VERSION "..\..\trunk\components\winTestMT\code\canApi\dbcFiles\canBus_07.dbc, created by Octave and generateRandomDbc.m on 21-Feb-2017"

NS_ :

BS_:

BU_: ECU

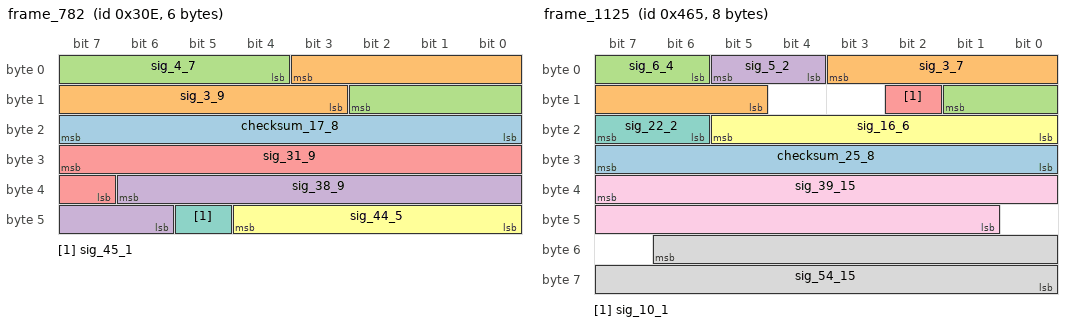
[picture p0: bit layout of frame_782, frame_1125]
BO_ 782 frame_782: 6 ECU
  SG_ checksum_17_8 : 23|8@0+ (1.0,0.0) [0.0|255.0] "" Vector__XXX
  SG_ sig_3_9 : 3|9@0- (1.0000000000000008E-8,3.162277660168379E-6) [6.02277660168377E-7|5.702277660168382E-6] "m/s^2" Vector__XXX
  SG_ sig_4_7 : 4|7@1+ (100.0,3162.2776601683795) [3162.2776601683795|15762.27766016838] "A" Vector__XXX
  SG_ sig_38_9 : 38|9@0+ (10.0,3162.2776601683795) [3162.2776601683795|8262.27766016838] "kWh" Vector__XXX
  SG_ sig_31_9 : 31|9@0+ (100.0,31622.776601683792) [31622.776601683792|82622.77660168378] "s" Vector__XXX
  SG_ sig_44_5 : 44|5@0- (0.1,0.0) [-1.6|1.4000000000000001] "m/s^2" Vector__XXX
  SG_ sig_45_1 : 45|1@0+ (1.0,0.0) [0.0|1.0] "" Vector__XXX

BO_ 1125 frame_1125: 8 Vector__XXX
  SG_ checksum_25_8 : 31|8@0+ (1.0,0.0) [0.0|255.0] "" ECU
  SG_ sig_3_7 : 3|7@0+ (1.0,0.0) [0.0|126.0] "" ECU
  SG_ sig_6_4 : 6|4@1- (1.0,0.0) [-8.0|6.0] "" ECU
  SG_ sig_5_2 : 5|2@0+ (1.0,0.0) [0.0|3.0] "" ECU
  SG_ sig_10_1 : 10|1@0+ (1.0,0.0) [0.0|1.0] "" ECU
  SG_ sig_16_6 : 16|6@1+ (1.0,0.0) [0.0|62.0] "" ECU
  SG_ sig_22_2 : 22|2@1+ (1.0,0.0) [0.0|3.0] "" ECU
  SG_ sig_54_15 : 54|15@0+ (1.0,31622.776601683792) [31622.776601683792|64388.77660168379] "A" ECU
  SG_ sig_39_15 : 39|15@0+ (1.0000000000000005E-4,3.1622776601683795) [3.1622776601683795|6.438877660168381] "m/s^2" ECU

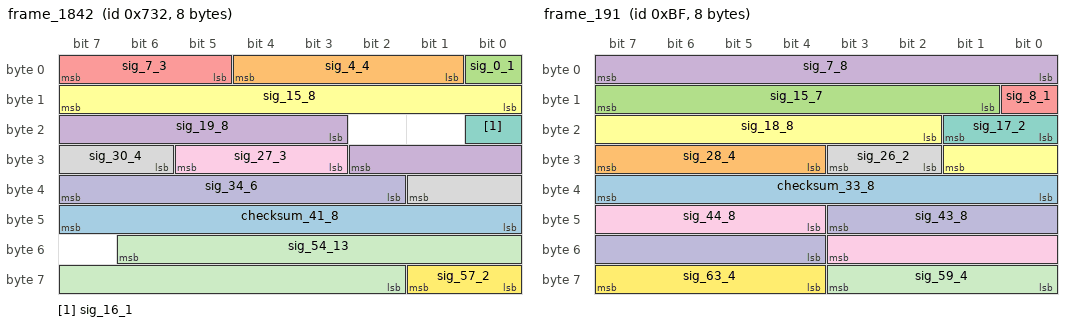
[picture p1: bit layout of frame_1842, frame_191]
BO_ 1842 frame_1842: 8 Vector__XXX
  SG_ checksum_41_8 : 47|8@0+ (1.0,0.0) [0.0|255.0] "" ECU
  SG_ sig_4_4 : 4|4@0+ (10000.0,0.0) [0.0|140000.0] "A" ECU
  SG_ sig_0_1 : 0|1@1+ (1.0,0.0) [0.0|1.0] "" ECU
  SG_ sig_19_8 : 19|8@1+ (1.0,0.0) [0.0|254.0] "A" ECU
  SG_ sig_7_3 : 7|3@0- (1.0,0.0) [-4.0|2.0] "" ECU
  SG_ sig_15_8 : 15|8@0+ (10.0,316.22776601683796) [316.22776601683796|2856.227766016838] "s" ECU
  SG_ sig_16_1 : 16|1@1+ (1.0,0.0) [0.0|1.0] "" ECU
  SG_ sig_30_4 : 30|4@1+ (10000.0,0.0) [0.0|140000.0] "A" ECU
  SG_ sig_27_3 : 27|3@1+ (1.0,0.0) [0.0|6.0] "" ECU
  SG_ sig_34_6 : 34|6@1+ (1.0000000000000006E-6,0.0) [0.0|6.200000000000004E-5] "kWh" ECU
  SG_ sig_54_13 : 54|13@0+ (10.0,-31622.776601683792) [-31622.776601683792|50277.22339831621] "A" ECU
  SG_ sig_57_2 : 57|2@0+ (1.0,0.0) [0.0|3.0] "" ECU

BO_ 1429 frame_1429: 4 Vector__XXX
  SG_ checksum_17_8 : 23|8@0+ (1.0,0.0) [0.0|255.0] "" ECU
  SG_ sig_3_10 : 3|10@0+ (0.010000000000000002,-3.1622776601683795) [-3.1622776601683795|7.0577223398316224] "A" ECU
  SG_ sig_7_4 : 7|4@0+ (0.010000000000000002,0.0) [0.0|0.14] "kWh" ECU
  SG_ sig_9_2 : 9|2@0- (1.0,0.0) [-2.0|1.0] "" ECU
  SG_ sig_31_8 : 31|8@0+ (1000.0,-31622.776601683792) [-31622.776601683792|222377.22339831622] "A" ECU

BO_ 191 frame_191: 8 Vector__XXX
  SG_ checksum_33_8 : 32|8@1+ (1.0,0.0) [0.0|255.0] "" ECU
  SG_ sig_28_4 : 28|4@1+ (10.0,0.0) [0.0|140.0] "km/h" ECU
  SG_ sig_15_7 : 15|7@0- (1.0,0.0) [-64.0|62.0] "" ECU
  SG_ sig_7_8 : 7|8@0- (1000.0,0.0) [-128000.0|126000.0] "A" ECU
  SG_ sig_8_1 : 8|1@1+ (1.0,0.0) [0.0|1.0] "" ECU
  SG_ sig_18_8 : 18|8@1+ (1.0000000000000005E-4,0.0) [0.0|0.025400000000000013] "W" ECU
  SG_ sig_17_2 : 17|2@0+ (1.0,0.0) [0.0|3.0] "" ECU
  SG_ sig_26_2 : 26|2@1- (1.0,0.0) [-2.0|1.0] "" ECU
  SG_ sig_44_8 : 44|8@1+ (1.0000000000000006E-6,0.0) [0.0|2.5400000000000016E-4] "s" ECU
  SG_ sig_43_8 : 43|8@0+ (0.010000000000000002,0.0) [0.0|2.5400000000000005] "s" ECU
  SG_ sig_59_4 : 59|4@0+ (1.0000000000000006E-6,0.0) [0.0|1.4000000000000008E-5] "kWh" ECU
  SG_ sig_63_4 : 63|4@0+ (1.0,0.0) [0.0|14.0] "m/s^2" ECU

BO_ 1867 frame_1867: 4 ECU
  SG_ checksum_1_8 : 0|8@1+ (1.0,0.0) [0.0|255.0] "" Vector__XXX
  SG_ sig_10_7 : 10|7@0+ (1.0000000000000006E-6,-3.1622776601683795E-5) [-3.1622776601683795E-5|9.437722339831629E-5] "V" Vector__XXX
  SG_ sig_15_5 : 15|5@0+ (0.1,0.0) [0.0|3.0] "m/s^2" Vector__XXX
  SG_ sig_17_10 : 17|10@0+ (10.0,0.0) [0.0|10220.0] "A" Vector__XXX
  SG_ sig_19_2 : 19|2@0+ (1.0,0.0) [0.0|3.0] "" Vector__XXX

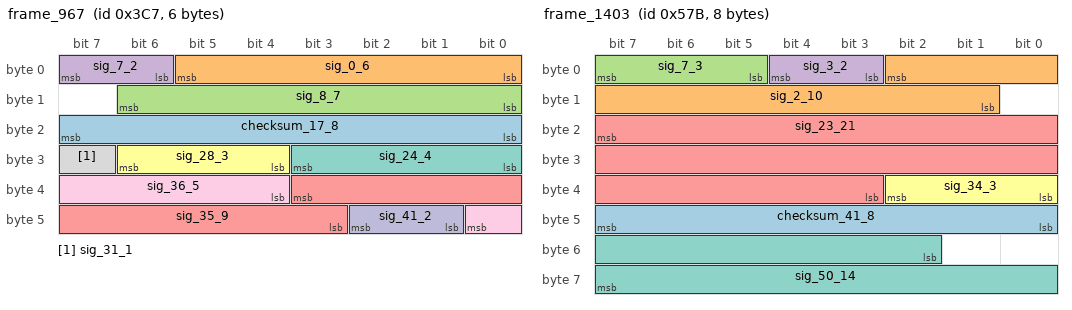
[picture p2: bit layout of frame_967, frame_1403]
BO_ 967 frame_967: 6 Vector__XXX
  SG_ checksum_17_8 : 16|8@1+ (1.0,0.0) [0.0|255.0] "" ECU
  SG_ sig_0_6 : 0|6@1+ (1.0000000000000007E-7,-3.162277660168379E-6) [-3.162277660168379E-6|3.037722339831626E-6] "A" ECU
  SG_ sig_8_7 : 8|7@1- (0.1,3.1622776601683795) [-3.237722339831621|9.36227766016838] "A" ECU
  SG_ sig_7_2 : 7|2@0+ (1.0,0.0) [0.0|3.0] "" ECU
  SG_ sig_35_9 : 35|9@0- (1.0000000000000006E-6,3.1622776601683794E-4) [6.022776601683779E-5|5.70227766016838E-4] "A" ECU
  SG_ sig_28_3 : 28|3@1- (1.0,0.0) [-4.0|2.0] "" ECU
  SG_ sig_24_4 : 24|4@1- (1.0,0.0) [-8.0|6.0] "" ECU
  SG_ sig_31_1 : 31|1@1+ (1.0,0.0) [0.0|1.0] "" ECU
  SG_ sig_36_5 : 36|5@1- (1.0,0.0) [-16.0|14.0] "" ECU
  SG_ sig_41_2 : 41|2@1+ (1.0,0.0) [0.0|3.0] "" ECU

BO_ 61 frame_61: 7 ECU
  SG_ checksum_17_8 : 23|8@0+ (1.0,0.0) [0.0|255.0] "" Vector__XXX
  SG_ sig_46_13 : 46|13@0- (1.0,0.0) [-4096.0|4094.0] "" Vector__XXX
  SG_ sig_47_3 : 47|3@1+ (1.0,0.0) [0.0|6.0] "" Vector__XXX

BO_ 1403 frame_1403: 8 ECU
  SG_ checksum_41_8 : 40|8@1+ (1.0,0.0) [0.0|255.0] "" Vector__XXX
  SG_ sig_2_10 : 2|10@0+ (1.0,0.0) [0.0|1022.0] "" Vector__XXX
  SG_ sig_7_3 : 7|3@0- (1.0,0.0) [-4.0|2.0] "" Vector__XXX
  SG_ sig_3_2 : 3|2@1+ (1.0,0.0) [0.0|3.0] "" Vector__XXX
  SG_ sig_23_21 : 23|21@0- (0.010000000000000002,-3162.2776601683795) [-13648.037660168382|7323.462339831622] "s" Vector__XXX
  SG_ sig_34_3 : 34|3@0- (1.0,0.0) [-4.0|2.0] "" Vector__XXX
  SG_ sig_50_14 : 50|14@1- (1.0000000000000009E-9,-3.162277660168379E-6) [-1.1354277660168386E-5|5.027722339831629E-6] "m/s^2" Vector__XXX

BO_ 1948 frame_1948: 6 Vector__XXX
  SG_ checksum_9_8 : 8|8@1+ (1.0,0.0) [0.0|255.0] "" ECU
  SG_ sig_0_8 : 0|8@1- (1.0000000000000007E-7,0.0) [-1.280000000000001E-5|1.260000000000001E-5] "m/s^2" ECU
  SG_ sig_21_10 : 21|10@1- (1.0,0.0) [-512.0|510.0] "" ECU
  SG_ sig_16_5 : 16|5@1- (1.0,0.0) [-16.0|14.0] "" ECU

BO_ 462 frame_462: 3 Vector__XXX
  SG_ checksum_17_8 : 23|8@0+ (1.0,0.0) [0.0|255.0] "" ECU
  SG_ sig_7_12 : 7|12@0- (0.0010000000000000002,-3.1622776601683795) [-5.21027766016838|-1.1162776601683788] "km/h" ECU
  SG_ sig_10_3 : 10|3@0+ (1.0,0.0) [0.0|6.0] "" ECU
  SG_ sig_11_1 : 11|1@0+ (1.0,0.0) [0.0|1.0] "" ECU

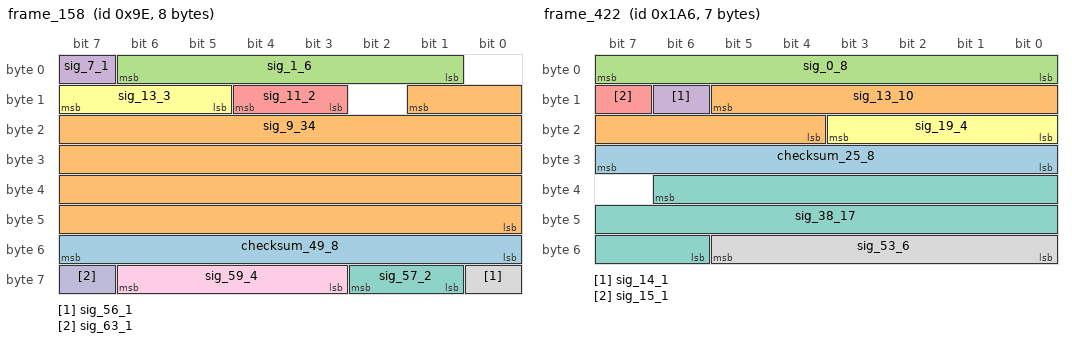
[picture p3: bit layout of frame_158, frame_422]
BO_ 158 frame_158: 8 ECU
  SG_ checksum_49_8 : 55|8@0+ (1.0,0.0) [0.0|255.0] "" Vector__XXX
  SG_ sig_9_34 : 9|34@0+ (1.0000000000000009E-9,3.1622776601683795) [3.1622776601683795|20.342146842168393] "m/s^2" Vector__XXX
  SG_ sig_1_6 : 1|6@1+ (0.0010000000000000002,0.03162277660168379) [0.03162277660168379|0.0936227766016838] "V" Vector__XXX
  SG_ sig_7_1 : 7|1@0+ (1.0,0.0) [0.0|1.0] "" Vector__XXX
  SG_ sig_11_2 : 11|2@1+ (1.0,0.0) [0.0|3.0] "" Vector__XXX
  SG_ sig_13_3 : 13|3@1- (1.0,0.0) [-4.0|2.0] "" Vector__XXX
  SG_ sig_57_2 : 57|2@1+ (1.0,0.0) [0.0|3.0] "" Vector__XXX
  SG_ sig_56_1 : 56|1@1+ (1.0,0.0) [0.0|1.0] "" Vector__XXX
  SG_ sig_59_4 : 59|4@1- (1.0,0.0) [-8.0|6.0] "" Vector__XXX
  SG_ sig_63_1 : 63|1@0+ (1.0,0.0) [0.0|1.0] "" Vector__XXX

BO_ 673 frame_673: 6 Vector__XXX
  SG_ checksum_25_8 : 31|8@0+ (1.0,0.0) [0.0|255.0] "" ECU
  SG_ sig_13_8 : 13|8@1- (1.0000000000000007E-7,-3.162277660168379E-6) [-1.596227766016839E-5|9.43772233983163E-6] "A" ECU
  SG_ sig_1_2 : 1|2@0- (1.0,0.0) [-2.0|1.0] "" ECU
  SG_ sig_12_1 : 12|1@0+ (1.0,0.0) [0.0|1.0] "" ECU
  SG_ sig_21_3 : 21|3@1+ (1.0,0.0) [0.0|6.0] "" ECU
  SG_ sig_37_12 : 37|12@0- (1.0000000000000006E-5,0.0) [-0.020480000000000012|0.020460000000000013] "m/s^2" ECU
  SG_ sig_41_1 : 41|1@0+ (1.0,0.0) [0.0|1.0] "" ECU

BO_ 422 frame_422: 7 Vector__XXX
  SG_ checksum_25_8 : 31|8@0+ (1.0,0.0) [0.0|255.0] "" ECU
  SG_ sig_13_10 : 13|10@0+ (1.0,0.0) [0.0|1022.0] "" ECU
  SG_ sig_0_8 : 0|8@1- (1.0000000000000005E-4,-0.0031622776601683794) [-0.015962277660168386|0.009437722339831625] "W" ECU
  SG_ sig_14_1 : 14|1@0+ (1.0,0.0) [0.0|1.0] "" ECU
  SG_ sig_15_1 : 15|1@0+ (1.0,0.0) [0.0|1.0] "" ECU
  SG_ sig_19_4 : 19|4@0+ (10.0,0.0) [0.0|140.0] "m/s^2" ECU
  SG_ sig_38_17 : 38|17@0- (1.0,0.0) [-65536.0|65534.0] "" ECU
  SG_ sig_53_6 : 53|6@0+ (1.0,0.0) [0.0|62.0] "" ECU

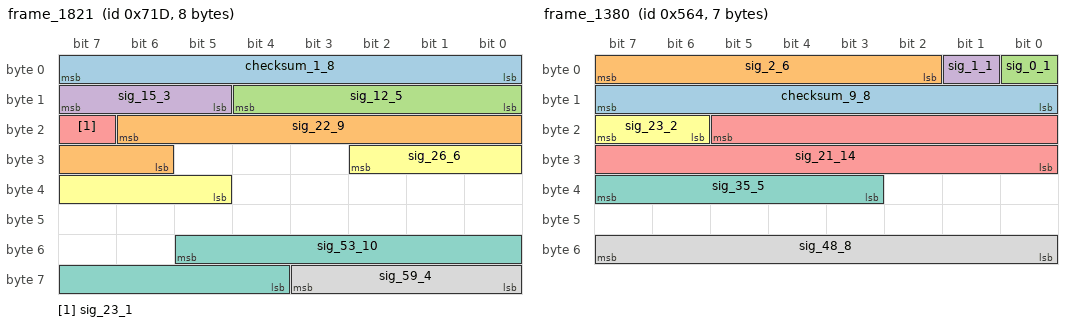
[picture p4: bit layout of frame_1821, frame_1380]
BO_ 1821 frame_1821: 8 Vector__XXX
  SG_ checksum_1_8 : 7|8@0+ (1.0,0.0) [0.0|255.0] "" ECU
  SG_ sig_22_9 : 22|9@0- (1.0,-316.22776601683796) [-572.2277660168379|-62.22776601683796] "kWh" ECU
  SG_ sig_12_5 : 12|5@0- (1.0,0.0) [-16.0|14.0] "" ECU
  SG_ sig_15_3 : 15|3@0- (1.0,0.0) [-4.0|2.0] "" ECU
  SG_ sig_23_1 : 23|1@0+ (1.0,0.0) [0.0|1.0] "" ECU
  SG_ sig_26_6 : 26|6@0+ (1.0000000000000005E-4,0.0031622776601683794) [0.0031622776601683794|0.009362277660168382] "W" ECU
  SG_ sig_53_10 : 53|10@0- (1.0000000000000008E-8,3.162277660168379E-6) [-1.957722339831625E-6|8.262277660168383E-6] "W" ECU
  SG_ sig_59_4 : 59|4@0- (10.0,0.0) [-80.0|60.0] "km/h" ECU

BO_ 1052 frame_1052: 3 ECU
  SG_ checksum_9_8 : 15|8@0+ (1.0,0.0) [0.0|255.0] "" Vector__XXX
  SG_ sig_7_8 : 7|8@0+ (0.1,0.0) [0.0|25.400000000000002] "W" Vector__XXX
  SG_ sig_22_7 : 22|7@0- (1.0,0.0) [-64.0|62.0] "" Vector__XXX
  SG_ sig_23_1 : 23|1@0+ (1.0,0.0) [0.0|1.0] "" Vector__XXX

BO_ 1380 frame_1380: 7 Vector__XXX
  SG_ checksum_9_8 : 8|8@1+ (1.0,0.0) [0.0|255.0] "" ECU
  SG_ sig_2_6 : 2|6@1- (1.0000000000000006E-5,-3.1622776601683794E-4) [-6.362277660168381E-4|-1.622776601683775E-5] "W" ECU
  SG_ sig_0_1 : 0|1@0+ (1.0,0.0) [0.0|1.0] "" ECU
  SG_ sig_1_1 : 1|1@1+ (1.0,0.0) [0.0|1.0] "" ECU
  SG_ sig_21_14 : 21|14@0+ (1.0000000000000007E-7,0.0) [0.0|0.0016382000000000013] "s" ECU
  SG_ sig_23_2 : 23|2@0+ (1.0,0.0) [0.0|3.0] "" ECU
  SG_ sig_35_5 : 35|5@1- (100.0,0.0) [-1600.0|1400.0] "V" ECU
  SG_ sig_48_8 : 48|8@1- (1.0,0.0) [-128.0|126.0] "" ECU

BO_ 1788 frame_1788: 3 Vector__XXX
  SG_ checksum_1_8 : 7|8@0+ (1.0,0.0) [0.0|255.0] "" ECU
  SG_ sig_13_14 : 13|14@0+ (1.0,0.0) [0.0|16382.0] "" ECU
  SG_ sig_15_2 : 15|2@0+ (1.0,0.0) [0.0|3.0] "" ECU

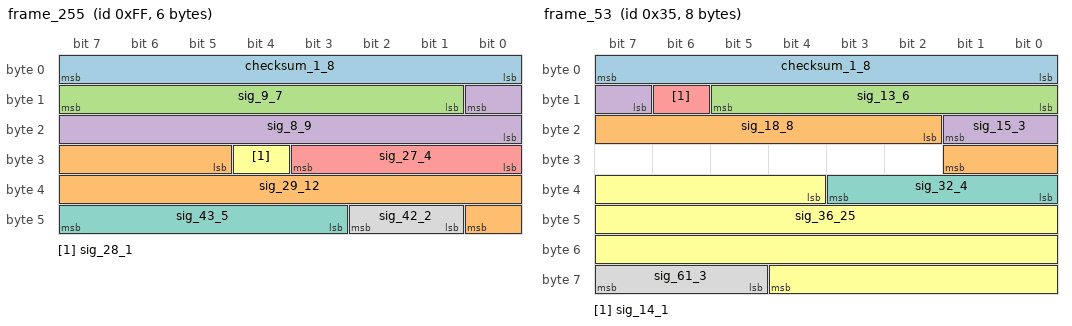
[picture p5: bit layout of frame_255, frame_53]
BO_ 255 frame_255: 6 Vector__XXX
  SG_ checksum_1_8 : 7|8@0+ (1.0,0.0) [0.0|255.0] "" ECU
  SG_ sig_29_12 : 29|12@1- (1.0,0.0) [-2048.0|2046.0] "" ECU
  SG_ sig_9_7 : 9|7@1- (1.0,0.0) [-64.0|62.0] "" ECU
  SG_ sig_8_9 : 8|9@0+ (0.0010000000000000002,-0.31622776601683794) [-0.31622776601683794|0.19377223398316218] "A" ECU
  SG_ sig_27_4 : 27|4@0- (0.1,0.31622776601683794) [-0.4837722339831621|0.9162277660168381] "W" ECU
  SG_ sig_28_1 : 28|1@1+ (1.0,0.0) [0.0|1.0] "" ECU
  SG_ sig_43_5 : 43|5@1+ (1.0000000000000006E-5,-3.1622776601683794E-4) [-3.1622776601683794E-4|-1.622776601683775E-5] "W" ECU
  SG_ sig_42_2 : 42|2@0+ (1.0,0.0) [0.0|3.0] "" ECU

BO_ 586 frame_586: 5 Vector__XXX
  SG_ checksum_17_8 : 16|8@1+ (1.0,0.0) [0.0|255.0] "" ECU
  SG_ sig_1_15 : 1|15@1+ (1.0,0.0) [0.0|32766.0] "" ECU
  SG_ sig_0_1 : 0|1@1+ (1.0,0.0) [0.0|1.0] "" ECU
  SG_ sig_26_8 : 26|8@1- (1.0,0.0) [-128.0|126.0] "" ECU
  SG_ sig_24_2 : 24|2@1+ (1.0,0.0) [0.0|3.0] "" ECU
  SG_ sig_35_5 : 35|5@1+ (1.0000000000000006E-5,3.1622776601683794E-4) [3.1622776601683794E-4|6.162277660168381E-4] "m/s^2" ECU
  SG_ sig_34_1 : 34|1@1+ (1.0,0.0) [0.0|1.0] "" ECU

BO_ 914 frame_914: 8 Vector__XXX
  SG_ checksum_33_8 : 39|8@0+ (1.0,0.0) [0.0|255.0] "" ECU
  SG_ sig_7_15 : 7|15@0- (1.0,0.0) [-16384.0|16382.0] "" ECU
  SG_ sig_8_17 : 8|17@0+ (1.0000000000000006E-6,0.0) [0.0|0.13107000000000008] "V" ECU
  SG_ sig_50_11 : 50|11@0- (1.0,0.0) [-1024.0|1022.0] "" ECU
  SG_ sig_47_13 : 47|13@0- (1.0000000000000008E-8,-3.1622776601683795E-5) [-7.258277660168383E-5|9.317223398316236E-6] "kWh" ECU

BO_ 565 frame_565: 5 Vector__XXX
  SG_ checksum_33_8 : 39|8@0+ (1.0,0.0) [0.0|255.0] "" ECU
  SG_ sig_6_24 : 6|24@1+ (1.000000000000001E-11,-3.1622776601683795E-5) [-3.1622776601683795E-5|1.361493633983164E-4] "m/s^2" ECU
  SG_ sig_5_1 : 5|1@0+ (1.0,0.0) [0.0|1.0] "" ECU
  SG_ sig_0_1 : 0|1@1+ (1.0,0.0) [0.0|1.0] "" ECU

BO_ 53 frame_53: 8 Vector__XXX
  SG_ checksum_1_8 : 0|8@1+ (1.0,0.0) [0.0|255.0] "" ECU
  SG_ sig_18_8 : 18|8@1+ (1.0,0.0) [0.0|254.0] "" ECU
  SG_ sig_13_6 : 13|6@0- (1.0,0.0) [-32.0|30.0] "" ECU
  SG_ sig_15_3 : 15|3@1- (1.0,0.0) [-4.0|2.0] "" ECU
  SG_ sig_14_1 : 14|1@1+ (1.0,0.0) [0.0|1.0] "" ECU
  SG_ sig_36_25 : 36|25@1- (1.0000000000000011E-10,-0.0031622776601683794) [-0.004839999260168381|-0.0014845562601683777] "kWh" ECU
  SG_ sig_32_4 : 32|4@1+ (1.0000000000000006E-5,0.0) [0.0|1.400000000000001E-4] "m/s^2" ECU
  SG_ sig_61_3 : 61|3@1+ (1.0,0.0) [0.0|6.0] "" ECU

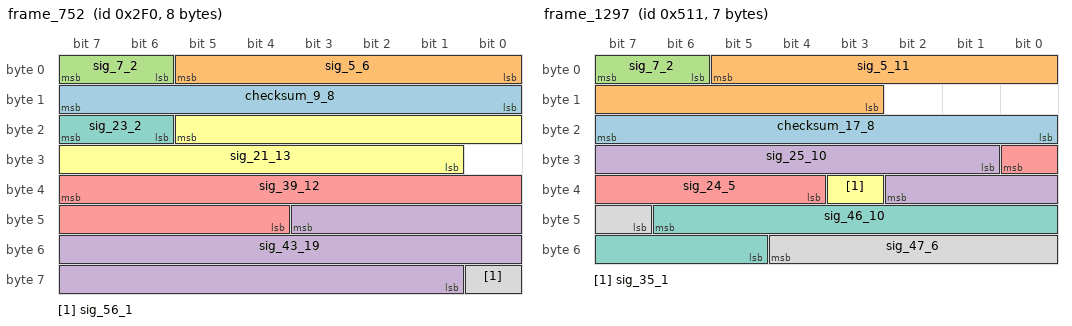
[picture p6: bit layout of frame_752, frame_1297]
BO_ 752 frame_752: 8 Vector__XXX
  SG_ checksum_9_8 : 15|8@0+ (1.0,0.0) [0.0|255.0] "" ECU
  SG_ sig_5_6 : 5|6@0- (1.0,31.622776601683793) [-0.37722339831620744|61.622776601683796] "V" ECU
  SG_ sig_7_2 : 7|2@0+ (1.0,0.0) [0.0|3.0] "" ECU
  SG_ sig_43_19 : 43|19@0+ (1.0000000000000005E-4,31.622776601683793) [31.622776601683793|84.05137660168381] "km/h" ECU
  SG_ sig_39_12 : 39|12@0- (1.0,0.0) [-2048.0|2046.0] "" ECU
  SG_ sig_21_13 : 21|13@0+ (1.0000000000000009E-9,-3.162277660168379E-6) [-3.162277660168379E-6|5.027722339831629E-6] "m/s^2" ECU
  SG_ sig_23_2 : 23|2@0- (1.0,0.0) [-2.0|1.0] "" ECU
  SG_ sig_56_1 : 56|1@0+ (1.0,0.0) [0.0|1.0] "" ECU

BO_ 1312 frame_1312: 4 Vector__XXX
  SG_ checksum_25_8 : 24|8@1+ (1.0,0.0) [0.0|255.0] "" ECU
  SG_ sig_15_10 : 15|10@0- (1.0,0.0) [-512.0|510.0] "" ECU
  SG_ sig_6_7 : 6|7@0- (1.0,-31.622776601683793) [-95.6227766016838|30.377223398316207] "V" ECU
  SG_ sig_7_1 : 7|1@0+ (1.0,0.0) [0.0|1.0] "" ECU
  SG_ sig_21_6 : 21|6@0+ (100.0,3162.2776601683795) [3162.2776601683795|9362.27766016838] "A" ECU

BO_ 863 frame_863: 7 Vector__XXX
  SG_ checksum_9_8 : 15|8@0+ (1.0,0.0) [0.0|255.0] "" ECU
  SG_ sig_0_8 : 0|8@1- (1.0000000000000006E-5,3.1622776601683794E-4) [-9.637722339831628E-4|0.0015762277660168386] "A" ECU
  SG_ sig_28_24 : 28|24@0+ (0.0010000000000000002,0.0) [0.0|16777.214000000004] "A" ECU
  SG_ sig_16_8 : 16|8@1- (1.0,0.0) [-128.0|126.0] "" ECU
  SG_ sig_31_3 : 31|3@0+ (1.0,0.0) [0.0|6.0] "" ECU
  SG_ sig_48_3 : 48|3@1+ (1.0,0.0) [0.0|6.0] "" ECU

BO_ 1297 frame_1297: 7 ECU
  SG_ checksum_17_8 : 16|8@1+ (1.0,0.0) [0.0|255.0] "" Vector__XXX
  SG_ sig_5_11 : 5|11@0+ (1.0,0.0) [0.0|2046.0] "m/s^2" Vector__XXX
  SG_ sig_7_2 : 7|2@0- (1.0,0.0) [-2.0|1.0] "" Vector__XXX
  SG_ sig_25_10 : 25|10@1- (1.0,0.0) [-512.0|510.0] "s" Vector__XXX
  SG_ sig_24_5 : 24|5@0+ (0.1,3.1622776601683795) [3.1622776601683795|6.16227766016838] "kWh" Vector__XXX
  SG_ sig_35_1 : 35|1@1+ (1.0,0.0) [0.0|1.0] "" Vector__XXX
  SG_ sig_46_10 : 46|10@0- (1.0000000000000007E-7,0.0) [-5.120000000000004E-5|5.100000000000004E-5] "W" Vector__XXX
  SG_ sig_47_6 : 47|6@1- (1.0000000000000006E-6,0.0) [-3.200000000000002E-5|3.0000000000000018E-5] "kWh" Vector__XXX

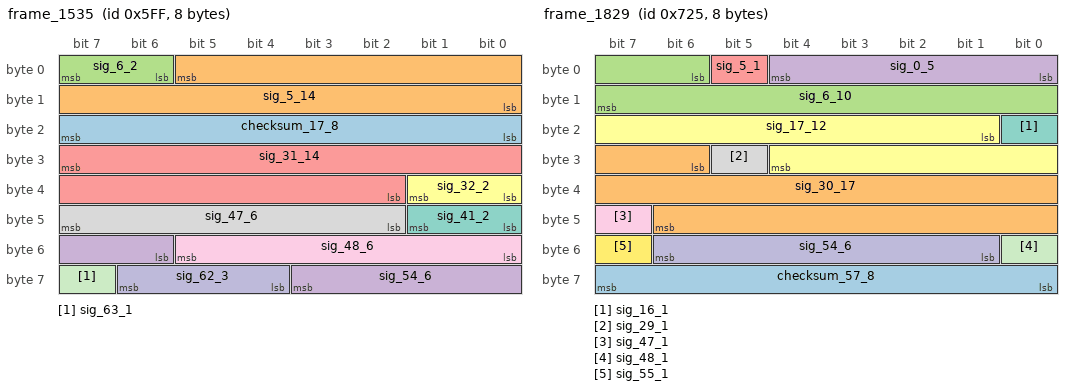
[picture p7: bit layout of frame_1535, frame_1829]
BO_ 1535 frame_1535: 8 Vector__XXX
  SG_ checksum_17_8 : 16|8@1+ (1.0,0.0) [0.0|255.0] "" ECU
  SG_ sig_5_14 : 5|14@0+ (0.1,316.22776601683796) [316.22776601683796|1954.427766016838] "m/s^2" ECU
  SG_ sig_6_2 : 6|2@1+ (1.0,0.0) [0.0|3.0] "" ECU
  SG_ sig_54_6 : 54|6@1- (1.0,0.0) [-32.0|30.0] "" ECU
  SG_ sig_31_14 : 31|14@0- (1.0000000000000005E-4,0.0) [-0.8192000000000004|0.8190000000000004] "s" ECU
  SG_ sig_32_2 : 32|2@1- (1.0,0.0) [-2.0|1.0] "" ECU
  SG_ sig_41_2 : 41|2@0- (1.0,0.0) [-2.0|1.0] "" ECU
  SG_ sig_47_6 : 47|6@0- (1.0,0.0) [-32.0|30.0] "" ECU
  SG_ sig_48_6 : 48|6@1- (1.0,0.0) [-32.0|30.0] "" ECU
  SG_ sig_62_3 : 62|3@0+ (1.0,0.0) [0.0|6.0] "" ECU
  SG_ sig_63_1 : 63|1@0+ (1.0,0.0) [0.0|1.0] "" ECU

BO_ 1829 frame_1829: 8 ECU
  SG_ checksum_57_8 : 63|8@0+ (1.0,0.0) [0.0|255.0] "" Vector__XXX
  SG_ sig_30_17 : 30|17@1+ (1.0,31622.776601683792) [31622.776601683792|162692.77660168378] "kWh" Vector__XXX
  SG_ sig_6_10 : 6|10@1- (0.1,0.0) [-51.2|51.0] "m/s^2" Vector__XXX
  SG_ sig_0_5 : 0|5@1+ (0.1,-3.1622776601683795) [-3.1622776601683795|-0.16227766016837952] "m/s^2" Vector__XXX
  SG_ sig_5_1 : 5|1@1+ (1.0,0.0) [0.0|1.0] "" Vector__XXX
  SG_ sig_17_12 : 17|12@1+ (1.0000000000000007E-7,3.1622776601683794E-4) [3.1622776601683794E-4|7.256277660168382E-4] "m/s^2" Vector__XXX
  SG_ sig_16_1 : 16|1@0+ (1.0,0.0) [0.0|1.0] "" Vector__XXX
  SG_ sig_29_1 : 29|1@1+ (1.0,0.0) [0.0|1.0] "" Vector__XXX
  SG_ sig_47_1 : 47|1@0+ (1.0,0.0) [0.0|1.0] "" Vector__XXX
  SG_ sig_54_6 : 54|6@0- (1.0,0.0) [-32.0|30.0] "" Vector__XXX
  SG_ sig_48_1 : 48|1@1+ (1.0,0.0) [0.0|1.0] "" Vector__XXX
  SG_ sig_55_1 : 55|1@1+ (1.0,0.0) [0.0|1.0] "" Vector__XXX

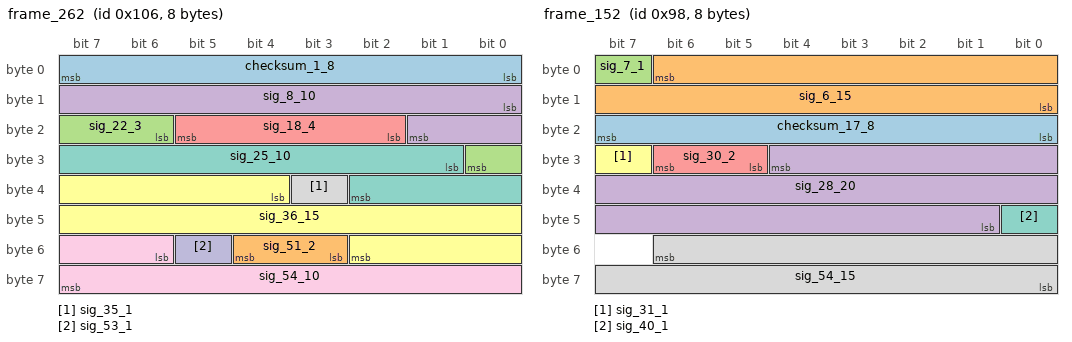
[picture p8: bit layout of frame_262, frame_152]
BO_ 262 frame_262: 8 Vector__XXX
  SG_ checksum_1_8 : 0|8@1+ (1.0,0.0) [0.0|255.0] "" ECU
  SG_ sig_51_2 : 51|2@1- (1.0,0.0) [-2.0|1.0] "" ECU
  SG_ sig_22_3 : 22|3@1+ (1.0,0.0) [0.0|6.0] "" ECU
  SG_ sig_8_10 : 8|10@1- (1.0000000000000008E-8,-3.162277660168379E-6) [-8.282277660168383E-6|1.9377223398316253E-6] "kWh" ECU
  SG_ sig_18_4 : 18|4@1- (10.0,31.622776601683793) [-48.377223398316204|91.6227766016838] "W" ECU
  SG_ sig_36_15 : 36|15@1+ (1.0000000000000006E-5,-0.31622776601683794) [-0.31622776601683794|0.011432233983162232] "m/s^2" ECU
  SG_ sig_25_10 : 25|10@1+ (0.1,-31.622776601683793) [-31.622776601683793|70.5772233983162] "A" ECU
  SG_ sig_35_1 : 35|1@1+ (1.0,0.0) [0.0|1.0] "" ECU
  SG_ sig_54_10 : 54|10@1+ (1.0,0.0) [0.0|1022.0] "" ECU
  SG_ sig_53_1 : 53|1@1+ (1.0,0.0) [0.0|1.0] "" ECU

BO_ 1208 frame_1208: 6 Vector__XXX
  SG_ checksum_25_8 : 24|8@1+ (1.0,0.0) [0.0|255.0] "" ECU
  SG_ sig_15_15 : 15|15@0+ (1.0,0.0) [0.0|32766.0] "" ECU
  SG_ sig_7_7 : 7|7@0+ (0.1,3.1622776601683795) [3.1622776601683795|15.762277660168381] "V" ECU
  SG_ sig_0_1 : 0|1@1+ (1.0,0.0) [0.0|1.0] "" ECU
  SG_ sig_16_1 : 16|1@1+ (1.0,0.0) [0.0|1.0] "" ECU
  SG_ sig_34_11 : 34|11@0- (1.0000000000000006E-5,-0.0031622776601683794) [-0.013402277660168386|0.007057722339831627] "km/h" ECU
  SG_ sig_35_5 : 35|5@1- (1.0,0.0) [-16.0|14.0] "" ECU

BO_ 1542 frame_1542: 5 Vector__XXX
  SG_ checksum_25_8 : 31|8@0+ (1.0,0.0) [0.0|255.0] "" ECU
  SG_ sig_12_12 : 12|12@0- (1.0000000000000006E-5,0.0) [-0.020480000000000012|0.020460000000000013] "m/s^2" ECU
  SG_ sig_0_7 : 0|7@1- (10.0,316.22776601683796) [-323.77223398316204|936.2277660168379] "km/h" ECU
  SG_ sig_7_1 : 7|1@1+ (1.0,0.0) [0.0|1.0] "" ECU
  SG_ sig_15_3 : 15|3@0- (1.0,0.0) [-4.0|2.0] "" ECU
  SG_ sig_16_1 : 16|1@1+ (1.0,0.0) [0.0|1.0] "" ECU
  SG_ sig_32_8 : 32|8@1- (10.0,-316.22776601683796) [-1596.227766016838|943.7722339831621] "A" ECU

BO_ 1341 frame_1341: 7 Vector__XXX
  SG_ checksum_41_8 : 40|8@1+ (1.0,0.0) [0.0|255.0] "" ECU
  SG_ sig_26_11 : 26|11@0- (1.0000000000000006E-6,3.1622776601683794E-4) [-7.077722339831627E-4|0.0013382277660168385] "A" ECU
  SG_ sig_19_9 : 19|9@0- (1.0000000000000006E-6,0.0) [-2.5600000000000015E-4|2.5400000000000016E-4] "km/h" ECU
  SG_ sig_48_8 : 48|8@1- (1.0,0.0) [-128.0|126.0] "" ECU

BO_ 1281 frame_1281: 6 ECU
  SG_ checksum_1_8 : 0|8@1+ (1.0,0.0) [0.0|255.0] "" Vector__XXX
  SG_ sig_13_17 : 13|17@1- (1.0000000000000007E-7,0.0) [-0.006553600000000005|0.006553400000000005] "V" Vector__XXX
  SG_ sig_11_4 : 11|4@0+ (1.0000000000000006E-6,3.162277660168379E-6) [3.162277660168379E-6|1.7162277660168386E-5] "kWh" Vector__XXX
  SG_ sig_12_1 : 12|1@1+ (1.0,0.0) [0.0|1.0] "" Vector__XXX
  SG_ sig_31_2 : 31|2@0+ (1.0,0.0) [0.0|3.0] "" Vector__XXX
  SG_ sig_39_15 : 39|15@0+ (1.0,-31622.776601683792) [-31622.776601683792|1143.2233983162077] "W" Vector__XXX
  SG_ sig_40_1 : 40|1@1+ (1.0,0.0) [0.0|1.0] "" Vector__XXX

BO_ 1119 frame_1119: 6 Vector__XXX
  SG_ checksum_1_8 : 0|8@1+ (1.0,0.0) [0.0|255.0] "" ECU
  SG_ sig_25_14 : 25|14@0- (1.0,0.0) [-8192.0|8190.0] "A" ECU
  SG_ sig_11_15 : 11|15@0+ (1.0000000000000011E-10,0.0) [0.0|3.2766000000000035E-6] "m/s^2" ECU
  SG_ sig_15_4 : 15|4@0- (1.0,0.0) [-8.0|6.0] "" ECU
  SG_ sig_28_3 : 28|3@0+ (1.0,0.0) [0.0|6.0] "" ECU
  SG_ sig_40_4 : 40|4@1+ (1.0,0.0) [0.0|14.0] "" ECU

BO_ 869 frame_869: 6 Vector__XXX
  SG_ checksum_1_8 : 0|8@1+ (1.0,0.0) [0.0|255.0] "" ECU
  SG_ sig_11_8 : 11|8@0+ (1.0,0.0) [0.0|254.0] "" ECU
  SG_ sig_15_3 : 15|3@0+ (1.0,0.0) [0.0|6.0] "" ECU
  SG_ sig_12_1 : 12|1@1+ (1.0,0.0) [0.0|1.0] "" ECU
  SG_ sig_16_4 : 16|4@1+ (1.0000000000000005E-4,3.1622776601683794E-4) [3.1622776601683794E-4|0.0017162277660168386] "s" ECU
  SG_ sig_30_18 : 30|18@0+ (1.0000000000000006E-6,-0.03162277660168379) [-0.03162277660168379|0.23051922339831638] "V" ECU

BO_ 1381 frame_1381: 8 Vector__XXX
  SG_ checksum_57_8 : 56|8@1+ (1.0,0.0) [0.0|255.0] "" ECU
  SG_ sig_0_54 : 0|54@1+ (1.0000000000000017E-16,0.31622776601683794) [0.31622776601683794|2.1176676169650395] "km/h" ECU
  SG_ sig_55_2 : 55|2@0+ (1.0,0.0) [0.0|3.0] "" ECU

BO_ 678 frame_678: 2 ECU
  SG_ checksum_1_8 : 7|8@0+ (1.0,0.0) [0.0|255.0] "" Vector__XXX
  SG_ sig_8_7 : 8|7@1+ (1000.0,0.0) [0.0|126000.0] "A" Vector__XXX
  SG_ sig_15_1 : 15|1@0+ (1.0,0.0) [0.0|1.0] "" Vector__XXX

BO_ 1157 frame_1157: 3 ECU
  SG_ checksum_9_8 : 15|8@0+ (1.0,0.0) [0.0|255.0] "" Vector__XXX
  SG_ sig_0_1 : 0|1@1+ (1.0,0.0) [0.0|1.0] "" Vector__XXX
  SG_ sig_16_7 : 16|7@1- (1.0000000000000006E-5,-3.1622776601683794E-4) [-9.562277660168383E-4|3.037722339831624E-4] "s" Vector__XXX
  SG_ sig_23_1 : 23|1@0+ (1.0,0.0) [0.0|1.0] "" Vector__XXX

BO_ 152 frame_152: 8 Vector__XXX
  SG_ checksum_17_8 : 16|8@1+ (1.0,0.0) [0.0|255.0] "" ECU
  SG_ sig_6_15 : 6|15@0+ (1.0000000000000005E-4,-3.1622776601683795) [-3.1622776601683795|0.11432233983162199] "W" ECU
  SG_ sig_7_1 : 7|1@1+ (1.0,0.0) [0.0|1.0] "" ECU
  SG_ sig_28_20 : 28|20@0+ (1.000000000000001E-11,-3.162277660168379E-6) [-3.162277660168379E-6|7.323462339831632E-6] "W" ECU
  SG_ sig_30_2 : 30|2@0- (1.0,0.0) [-2.0|1.0] "" ECU
  SG_ sig_31_1 : 31|1@0+ (1.0,0.0) [0.0|1.0] "" ECU
  SG_ sig_40_1 : 40|1@1+ (1.0,0.0) [0.0|1.0] "" ECU
  SG_ sig_54_15 : 54|15@0+ (1.0000000000000009E-9,0.0) [0.0|3.276600000000003E-5] "W" ECU

BO_ 1496 frame_1496: 6 Vector__XXX
  SG_ checksum_33_8 : 32|8@1+ (1.0,0.0) [0.0|255.0] "" ECU
  SG_ sig_1_10 : 1|10@1+ (1.0000000000000005E-4,0.0) [0.0|0.10220000000000004] "V" ECU
  SG_ sig_30_1 : 30|1@1+ (1.0,0.0) [0.0|1.0] "" ECU
  SG_ sig_31_1 : 31|1@0+ (1.0,0.0) [0.0|1.0] "" ECU
  SG_ sig_25_5 : 25|5@1- (1.0,0.0) [-16.0|14.0] "" ECU
  SG_ sig_40_8 : 40|8@1+ (0.010000000000000002,0.31622776601683794) [0.31622776601683794|2.8562277660168385] "s" ECU

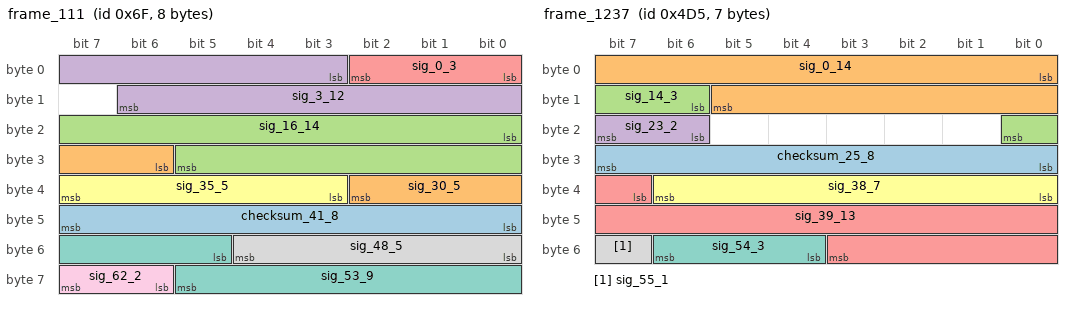
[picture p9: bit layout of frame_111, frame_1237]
BO_ 111 frame_111: 8 ECU
  SG_ checksum_41_8 : 40|8@1+ (1.0,0.0) [0.0|255.0] "" Vector__XXX
  SG_ sig_30_5 : 30|5@1+ (0.010000000000000002,0.31622776601683794) [0.31622776601683794|0.616227766016838] "km/h" Vector__XXX
  SG_ sig_16_14 : 16|14@1- (1.0,0.0) [-8192.0|8190.0] "" Vector__XXX
  SG_ sig_3_12 : 3|12@1- (1.0,0.0) [-2048.0|2046.0] "" Vector__XXX
  SG_ sig_0_3 : 0|3@1+ (1.0,0.0) [0.0|6.0] "" Vector__XXX
  SG_ sig_35_5 : 35|5@1+ (1.0000000000000006E-6,3.1622776601683795E-5) [3.1622776601683795E-5|6.162277660168381E-5] "kWh" Vector__XXX
  SG_ sig_53_9 : 53|9@1- (100.0,31622.776601683792) [6022.776601683792|57022.77660168379] "W" Vector__XXX
  SG_ sig_48_5 : 48|5@1+ (1.0,0.0) [0.0|30.0] "" Vector__XXX
  SG_ sig_62_2 : 62|2@1+ (1.0,0.0) [0.0|3.0] "" Vector__XXX

BO_ 1237 frame_1237: 7 Vector__XXX
  SG_ checksum_25_8 : 24|8@1+ (1.0,0.0) [0.0|255.0] "" ECU
  SG_ sig_0_14 : 0|14@1+ (1.0,0.0) [0.0|16382.0] "" ECU
  SG_ sig_14_3 : 14|3@1+ (1.0,0.0) [0.0|6.0] "" ECU
  SG_ sig_23_2 : 23|2@0+ (1.0,0.0) [0.0|3.0] "" ECU
  SG_ sig_39_13 : 39|13@1+ (1.0000000000000007E-7,-3.1622776601683794E-4) [-3.1622776601683794E-4|5.027722339831627E-4] "kWh" ECU
  SG_ sig_38_7 : 38|7@0- (10.0,316.22776601683796) [-323.77223398316204|936.2277660168379] "kWh" ECU
  SG_ sig_54_3 : 54|3@0+ (1.0,0.0) [0.0|6.0] "" ECU
  SG_ sig_55_1 : 55|1@1+ (1.0,0.0) [0.0|1.0] "" ECU

BO_ 509 frame_509: 6 ECU
  SG_ checksum_9_8 : 15|8@0+ (1.0,0.0) [0.0|255.0] "" Vector__XXX
  SG_ sig_7_7 : 7|7@0+ (1.0000000000000005E-4,-0.0031622776601683794) [-0.0031622776601683794|0.009437722339831625] "s" Vector__XXX
  SG_ sig_20_26 : 20|26@0- (1.0000000000000014E-12,-3.1622776601683795E-5) [-6.517720860168384E-5|1.9316533983162527E-6] "W" Vector__XXX
  SG_ sig_23_3 : 23|3@0+ (1.0,0.0) [0.0|6.0] "" Vector__XXX
  SG_ sig_42_3 : 42|3@0- (1.0,0.0) [-4.0|2.0] "" Vector__XXX

BO_ 927 frame_927: 4 Vector__XXX
  SG_ checksum_1_8 : 0|8@1+ (1.0,0.0) [0.0|255.0] "" ECU
  SG_ sig_9_14 : 9|14@1+ (1.0000000000000005E-4,0.31622776601683794) [0.31622776601683794|1.9544277660168388] "A" ECU
  SG_ sig_8_1 : 8|1@1+ (1.0,0.0) [0.0|1.0] "" ECU
  SG_ sig_23_8 : 23|8@1+ (1000.0,0.0) [0.0|254000.0] "V" ECU
  SG_ sig_31_1 : 31|1@1+ (1.0,0.0) [0.0|1.0] "" ECU

BO_ 199 frame_199: 4 ECU
  SG_ checksum_17_8 : 23|8@0+ (1.0,0.0) [0.0|255.0] "" Vector__XXX
  SG_ sig_3_11 : 3|11@1- (1.0000000000000006E-6,3.1622776601683794E-4) [-7.077722339831627E-4|0.0013382277660168385] "W" Vector__XXX
  SG_ sig_0_3 : 0|3@1+ (1.0,0.0) [0.0|6.0] "" Vector__XXX
  SG_ sig_14_2 : 14|2@1- (1.0,0.0) [-2.0|1.0] "" Vector__XXX
  SG_ sig_28_3 : 28|3@1- (1.0,0.0) [-4.0|2.0] "" Vector__XXX
  SG_ sig_31_1 : 31|1@0+ (1.0,0.0) [0.0|1.0] "" Vector__XXX
  SG_ sig_24_4 : 24|4@1+ (1.0,0.0) [0.0|14.0] "" Vector__XXX

BO_ 1601 frame_1601: 5 Vector__XXX
  SG_ checksum_1_8 : 7|8@0+ (1.0,0.0) [0.0|255.0] "" ECU
  SG_ sig_13_22 : 13|22@0- (1.0000000000000014E-12,-3.162277660168379E-6) [-5.259429660168382E-6|-1.0651276601683763E-6] "kWh" ECU
  SG_ sig_15_2 : 15|2@0- (1.0,0.0) [-2.0|1.0] "" ECU
  SG_ sig_33_6 : 33|6@1+ (1.0,0.0) [0.0|62.0] "" ECU
  SG_ sig_39_1 : 39|1@0+ (1.0,0.0) [0.0|1.0] "" ECU
  SG_ sig_32_1 : 32|1@0+ (1.0,0.0) [0.0|1.0] "" ECU

BO_ 1931 frame_1931: 5 ECU
  SG_ checksum_25_8 : 31|8@0+ (1.0,0.0) [0.0|255.0] "" Vector__XXX
  SG_ sig_1_14 : 1|14@0- (1.0000000000000007E-7,3.1622776601683794E-4) [-5.029722339831627E-4|0.0011352277660168384] "kWh" Vector__XXX
  SG_ sig_6_5 : 6|5@0+ (1.0,0.0) [0.0|30.0] "" Vector__XXX
  SG_ sig_7_1 : 7|1@0+ (1.0,0.0) [0.0|1.0] "" Vector__XXX
  SG_ sig_17_3 : 17|3@1- (1.0,0.0) [-4.0|2.0] "" Vector__XXX
  SG_ sig_39_8 : 39|8@0- (1.0000000000000005E-4,0.0) [-0.012800000000000006|0.012600000000000005] "V" Vector__XXX

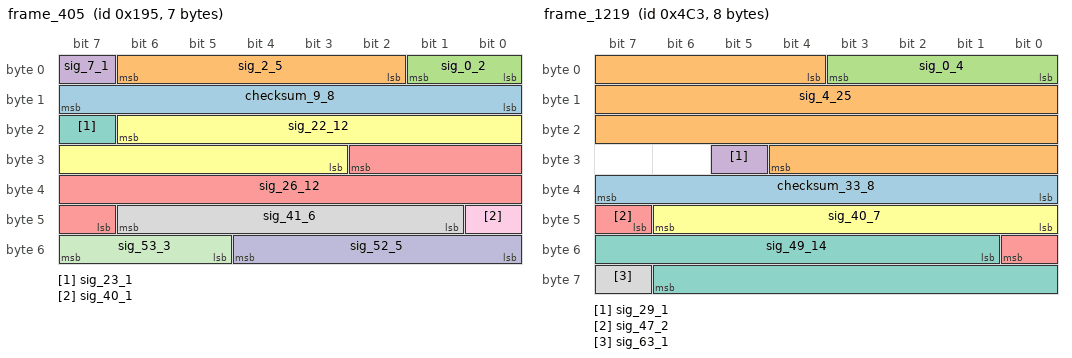
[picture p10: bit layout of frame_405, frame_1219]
BO_ 405 frame_405: 7 Vector__XXX
  SG_ checksum_9_8 : 8|8@1+ (1.0,0.0) [0.0|255.0] "" ECU
  SG_ sig_2_5 : 2|5@1+ (1.0,0.0) [0.0|30.0] "" ECU
  SG_ sig_0_2 : 0|2@1- (1.0,0.0) [-2.0|1.0] "" ECU
  SG_ sig_7_1 : 7|1@0+ (1.0,0.0) [0.0|1.0] "" ECU
  SG_ sig_26_12 : 26|12@0- (1.0000000000000008E-8,3.1622776601683795E-5) [1.1142776601683778E-5|5.208277660168381E-5] "km/h" ECU
  SG_ sig_22_12 : 22|12@0+ (1.0000000000000009E-9,3.162277660168379E-6) [3.162277660168379E-6|7.256277660168383E-6] "m/s^2" ECU
  SG_ sig_23_1 : 23|1@1+ (1.0,0.0) [0.0|1.0] "" ECU
  SG_ sig_41_6 : 41|6@1- (1.0000000000000006E-5,3.1622776601683794E-4) [-3.7722339831622494E-6|6.162277660168381E-4] "kWh" ECU
  SG_ sig_40_1 : 40|1@1+ (1.0,0.0) [0.0|1.0] "" ECU
  SG_ sig_52_5 : 52|5@0+ (0.010000000000000002,0.31622776601683794) [0.31622776601683794|0.616227766016838] "kWh" ECU
  SG_ sig_53_3 : 53|3@1- (1.0,0.0) [-4.0|2.0] "" ECU

BO_ 1219 frame_1219: 8 Vector__XXX
  SG_ checksum_33_8 : 39|8@0+ (1.0,0.0) [0.0|255.0] "" ECU
  SG_ sig_4_25 : 4|25@1- (0.0010000000000000002,31622.776601683792) [14845.560601683788|48399.99060168379] "A" ECU
  SG_ sig_0_4 : 0|4@1- (1.0,0.0) [-8.0|6.0] "" ECU
  SG_ sig_29_1 : 29|1@0+ (1.0,0.0) [0.0|1.0] "" ECU
  SG_ sig_47_2 : 47|2@1+ (1.0,0.0) [0.0|3.0] "" ECU
  SG_ sig_40_7 : 40|7@1- (1.0000000000000007E-7,0.0) [-6.400000000000005E-6|6.200000000000005E-6] "A" ECU
  SG_ sig_49_14 : 49|14@1+ (1.0,-3162.2776601683795) [-3162.2776601683795|13219.72233983162] "A" ECU
  SG_ sig_63_1 : 63|1@1+ (1.0,0.0) [0.0|1.0] "" ECU

BO_ 788 frame_788: 5 Vector__XXX
  SG_ checksum_17_8 : 23|8@0+ (1.0,0.0) [0.0|255.0] "" ECU
  SG_ sig_1_12 : 1|12@1- (1.0000000000000008E-8,3.1622776601683795E-5) [1.1142776601683778E-5|5.208277660168381E-5] "m/s^2" ECU
  SG_ sig_0_3 : 0|3@0- (1.0,0.0) [-4.0|2.0] "" ECU
  SG_ sig_13_1 : 13|1@1+ (1.0,0.0) [0.0|1.0] "" ECU
  SG_ sig_25_10 : 25|10@0+ (1.0,0.0) [0.0|1022.0] "" ECU
  SG_ sig_31_6 : 31|6@0+ (1.0000000000000006E-5,3.1622776601683794E-4) [3.1622776601683794E-4|9.362277660168383E-4] "s" ECU

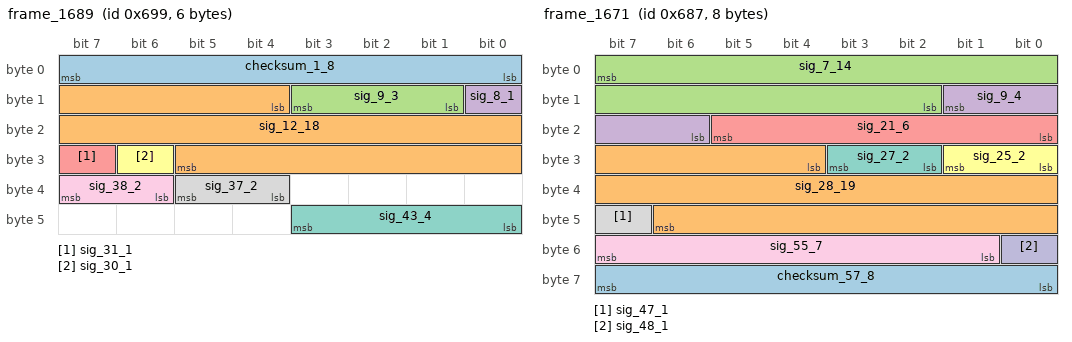
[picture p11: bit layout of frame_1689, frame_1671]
BO_ 1689 frame_1689: 6 Vector__XXX
  SG_ checksum_1_8 : 7|8@0+ (1.0,0.0) [0.0|255.0] "" ECU
  SG_ sig_12_18 : 12|18@1- (1.0,31622.776601683792) [-99449.22339831622|162692.77660168378] "W" ECU
  SG_ sig_9_3 : 9|3@1+ (1.0,0.0) [0.0|6.0] "" ECU
  SG_ sig_8_1 : 8|1@1+ (1.0,0.0) [0.0|1.0] "" ECU
  SG_ sig_31_1 : 31|1@0+ (1.0,0.0) [0.0|1.0] "" ECU
  SG_ sig_30_1 : 30|1@0+ (1.0,0.0) [0.0|1.0] "" ECU
  SG_ sig_43_4 : 43|4@0+ (0.1,0.31622776601683794) [0.31622776601683794|1.7162277660168381] "s" ECU
  SG_ sig_37_2 : 37|2@0- (1.0,0.0) [-2.0|1.0] "" ECU
  SG_ sig_38_2 : 38|2@1+ (1.0,0.0) [0.0|3.0] "" ECU

BO_ 42 frame_42: 8 Vector__XXX
  SG_ checksum_17_8 : 23|8@0+ (1.0,0.0) [0.0|255.0] "" ECU
  SG_ sig_7_15 : 7|15@0+ (1.0,0.0) [0.0|32766.0] "" ECU
  SG_ sig_8_1 : 8|1@1+ (1.0,0.0) [0.0|1.0] "" ECU
  SG_ sig_31_25 : 31|25@1- (1.0000000000000006E-5,316.22776601683796) [148.45560601683786|483.99990601683805] "kWh" ECU
  SG_ sig_24_5 : 24|5@1+ (1000.0,-31622.776601683792) [-31622.776601683792|-1622.7766016837923] "m/s^2" ECU
  SG_ sig_30_2 : 30|2@0+ (1.0,0.0) [0.0|3.0] "" ECU
  SG_ sig_57_6 : 57|6@1- (0.0010000000000000002,-0.03162277660168379) [-0.0636227766016838|-0.0016227766016837855] "km/h" ECU

BO_ 1671 frame_1671: 8 Vector__XXX
  SG_ checksum_57_8 : 63|8@0+ (1.0,0.0) [0.0|255.0] "" ECU
  SG_ sig_28_19 : 28|19@1+ (0.010000000000000002,3162.2776601683795) [3162.2776601683795|8405.13766016838] "kWh" ECU
  SG_ sig_7_14 : 7|14@0+ (0.010000000000000002,-31.622776601683793) [-31.622776601683793|132.19722339831623] "m/s^2" ECU
  SG_ sig_9_4 : 9|4@0- (1.0,0.0) [-8.0|6.0] "" ECU
  SG_ sig_21_6 : 21|6@0- (10.0,-316.22776601683796) [-636.2277660168379|-16.22776601683796] "A" ECU
  SG_ sig_25_2 : 25|2@0+ (1.0,0.0) [0.0|3.0] "" ECU
  SG_ sig_27_2 : 27|2@0+ (1.0,0.0) [0.0|3.0] "" ECU
  SG_ sig_47_1 : 47|1@0+ (1.0,0.0) [0.0|1.0] "" ECU
  SG_ sig_55_7 : 55|7@0+ (1.0000000000000005E-4,-0.0031622776601683794) [-0.0031622776601683794|0.009437722339831625] "s" ECU
  SG_ sig_48_1 : 48|1@0+ (1.0,0.0) [0.0|1.0] "" ECU

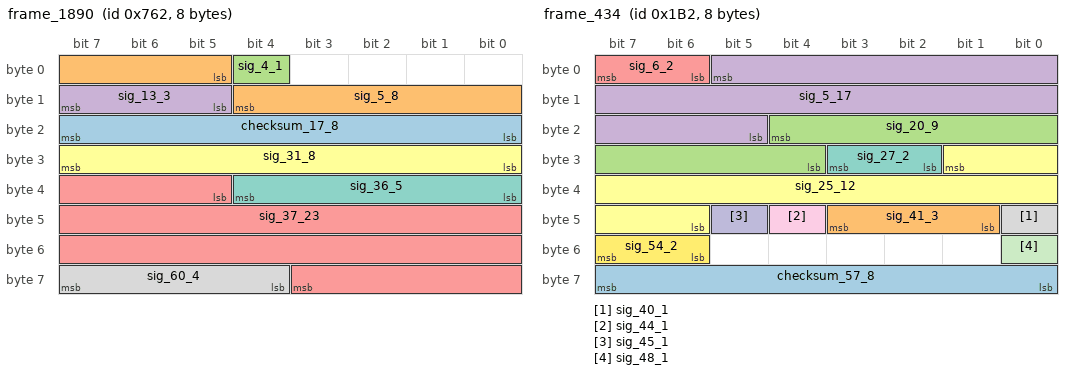
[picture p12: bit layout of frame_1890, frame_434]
BO_ 1890 frame_1890: 8 Vector__XXX
  SG_ checksum_17_8 : 16|8@1+ (1.0,0.0) [0.0|255.0] "" ECU
  SG_ sig_5_8 : 5|8@1- (0.0010000000000000002,0.03162277660168379) [-0.09637722339831624|0.15762277660168383] "kWh" ECU
  SG_ sig_4_1 : 4|1@1+ (1.0,0.0) [0.0|1.0] "" ECU
  SG_ sig_13_3 : 13|3@1- (1.0,0.0) [-4.0|2.0] "" ECU
  SG_ sig_37_23 : 37|23@1+ (1.0000000000000011E-10,3.1622776601683794E-4) [3.1622776601683794E-4|0.0011550883660168389] "s" ECU
  SG_ sig_31_8 : 31|8@0+ (1.0000000000000005E-4,0.0031622776601683794) [0.0031622776601683794|0.028562277660168393] "km/h" ECU
  SG_ sig_36_5 : 36|5@0- (100.0,3162.2776601683795) [1562.2776601683795|4562.27766016838] "s" ECU
  SG_ sig_60_4 : 60|4@1+ (10.0,31.622776601683793) [31.622776601683793|171.6227766016838] "A" ECU

BO_ 434 frame_434: 8 Vector__XXX
  SG_ checksum_57_8 : 63|8@0+ (1.0,0.0) [0.0|255.0] "" ECU
  SG_ sig_41_3 : 41|3@1- (1.0,0.0) [-4.0|2.0] "" ECU
  SG_ sig_20_9 : 20|9@0+ (1.0,0.0) [0.0|510.0] "" ECU
  SG_ sig_5_17 : 5|17@0+ (0.010000000000000002,0.0) [0.0|1310.7000000000003] "A" ECU
  SG_ sig_6_2 : 6|2@1+ (1.0,0.0) [0.0|3.0] "" ECU
  SG_ sig_25_12 : 25|12@0+ (1.0,-3162.2776601683795) [-3162.2776601683795|931.7223398316205] "km/h" ECU
  SG_ sig_27_2 : 27|2@0+ (1.0,0.0) [0.0|3.0] "" ECU
  SG_ sig_40_1 : 40|1@1+ (1.0,0.0) [0.0|1.0] "" ECU
  SG_ sig_44_1 : 44|1@0+ (1.0,0.0) [0.0|1.0] "" ECU
  SG_ sig_45_1 : 45|1@1+ (1.0,0.0) [0.0|1.0] "" ECU
  SG_ sig_48_1 : 48|1@1+ (1.0,0.0) [0.0|1.0] "" ECU
  SG_ sig_54_2 : 54|2@1- (1.0,0.0) [-2.0|1.0] "" ECU

BO_ 1389 frame_1389: 4 Vector__XXX
  SG_ checksum_9_8 : 8|8@1+ (1.0,0.0) [0.0|255.0] "" ECU
  SG_ sig_7_8 : 7|8@0+ (1.0,0.0) [0.0|254.0] "" ECU
  SG_ sig_17_10 : 17|10@1+ (1.0,316.22776601683796) [316.22776601683796|1338.227766016838] "m/s^2" ECU
  SG_ sig_31_4 : 31|4@0+ (0.0010000000000000002,-0.0031622776601683794) [-0.0031622776601683794|0.010837722339831624] "m/s^2" ECU
  SG_ sig_16_1 : 16|1@0+ (1.0,0.0) [0.0|1.0] "" ECU
  SG_ sig_27_1 : 27|1@1+ (1.0,0.0) [0.0|1.0] "" ECU

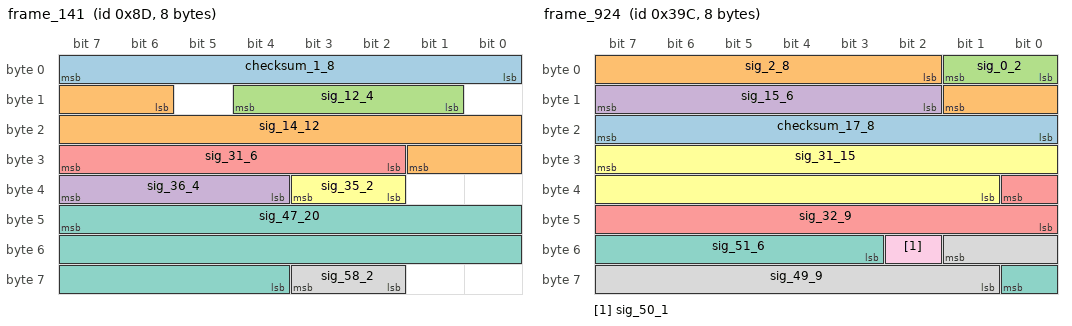
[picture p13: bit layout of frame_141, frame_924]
BO_ 141 frame_141: 8 Vector__XXX
  SG_ checksum_1_8 : 7|8@0+ (1.0,0.0) [0.0|255.0] "" ECU
  SG_ sig_14_12 : 14|12@1- (0.0010000000000000002,-3.1622776601683795) [-5.21027766016838|-1.1162776601683788] "km/h" ECU
  SG_ sig_12_4 : 12|4@0- (1.0,0.0) [-8.0|6.0] "" ECU
  SG_ sig_36_4 : 36|4@1+ (1.0,0.0) [0.0|14.0] "" ECU
  SG_ sig_31_6 : 31|6@0- (1.0,0.0) [-32.0|30.0] "" ECU
  SG_ sig_35_2 : 35|2@0+ (1.0,0.0) [0.0|3.0] "" ECU
  SG_ sig_47_20 : 47|20@0+ (1.0000000000000007E-7,-0.03162277660168379) [-0.03162277660168379|0.07323462339831628] "kWh" ECU
  SG_ sig_58_2 : 58|2@1+ (1.0,0.0) [0.0|3.0] "" ECU

BO_ 1524 frame_1524: 6 ECU
  SG_ checksum_9_8 : 15|8@0+ (1.0,0.0) [0.0|255.0] "" Vector__XXX
  SG_ sig_7_8 : 7|8@0+ (1.0,0.0) [0.0|254.0] "" Vector__XXX
  SG_ sig_25_15 : 25|15@0- (1.0000000000000006E-5,0.0) [-0.1638400000000001|0.1638200000000001] "s" Vector__XXX
  SG_ sig_17_8 : 17|8@0- (1.0000000000000007E-7,0.0) [-1.280000000000001E-5|1.260000000000001E-5] "V" Vector__XXX
  SG_ sig_23_6 : 23|6@0- (1.0000000000000006E-6,3.1622776601683795E-5) [-3.772233983162236E-7|6.162277660168381E-5] "V" Vector__XXX
  SG_ sig_42_3 : 42|3@0- (1.0,0.0) [-4.0|2.0] "" Vector__XXX

BO_ 924 frame_924: 8 ECU
  SG_ checksum_17_8 : 23|8@0+ (1.0,0.0) [0.0|255.0] "" Vector__XXX
  SG_ sig_2_8 : 2|8@1+ (0.010000000000000002,0.0) [0.0|2.5400000000000005] "V" Vector__XXX
  SG_ sig_0_2 : 0|2@1- (1.0,0.0) [-2.0|1.0] "" Vector__XXX
  SG_ sig_15_6 : 15|6@0+ (1.0,0.0) [0.0|62.0] "" Vector__XXX
  SG_ sig_32_9 : 32|9@0+ (1.0,0.0) [0.0|510.0] "" Vector__XXX
  SG_ sig_31_15 : 31|15@0+ (0.010000000000000002,-316.22776601683796) [-316.22776601683796|11.43223398316212] "kWh" Vector__XXX
  SG_ sig_51_6 : 51|6@1- (1.0000000000000005E-4,-0.0031622776601683794) [-0.006362277660168381|-1.6227766016837803E-4] "A" Vector__XXX
  SG_ sig_49_9 : 49|9@0- (1.0,-316.22776601683796) [-572.2277660168379|-62.22776601683796] "kWh" Vector__XXX
  SG_ sig_50_1 : 50|1@1+ (1.0,0.0) [0.0|1.0] "" Vector__XXX

BO_ 1022 frame_1022: 7 ECU
  SG_ checksum_41_8 : 40|8@1+ (1.0,0.0) [0.0|255.0] "" Vector__XXX
  SG_ sig_16_12 : 16|12@1- (10.0,31622.776601683792) [11142.776601683792|52082.77660168379] "W" Vector__XXX
  SG_ sig_0_15 : 0|15@1+ (1.0,0.0) [0.0|32766.0] "km/h" Vector__XXX
  SG_ sig_15_1 : 15|1@1+ (1.0,0.0) [0.0|1.0] "" Vector__XXX
  SG_ sig_28_12 : 28|12@1+ (1.0000000000000006E-5,0.0) [0.0|0.040940000000000025] "W" Vector__XXX
  SG_ sig_48_8 : 48|8@1- (0.1,-3.1622776601683795) [-15.96227766016838|9.437722339831621] "s" Vector__XXX

BO_ 412 frame_412: 6 Vector__XXX
  SG_ checksum_1_8 : 7|8@0+ (1.0,0.0) [0.0|255.0] "" ECU
  SG_ sig_22_23 : 22|23@1+ (1.0000000000000008E-8,0.03162277660168379) [0.03162277660168379|0.11550883660168386] "kWh" ECU
  SG_ sig_9_11 : 9|11@1- (1.0,0.0) [-1024.0|1022.0] "" ECU
  SG_ sig_21_2 : 21|2@0- (1.0,0.0) [-2.0|1.0] "" ECU
  SG_ sig_45_3 : 45|3@1+ (1.0,0.0) [0.0|6.0] "" ECU

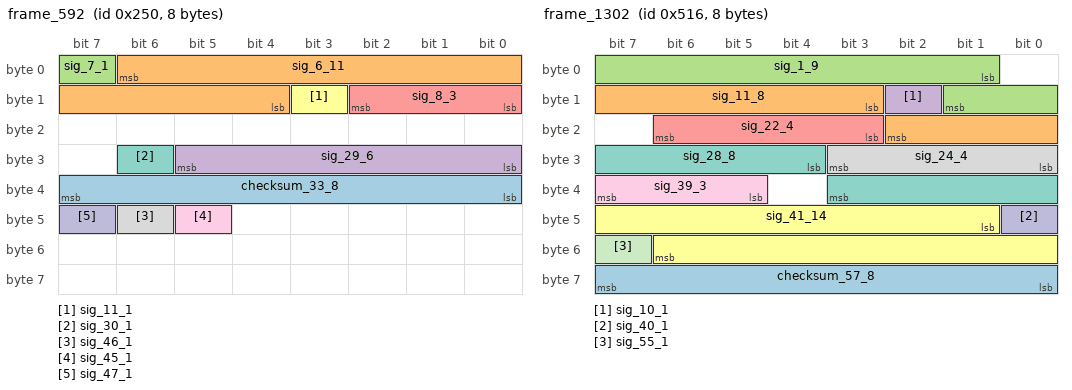
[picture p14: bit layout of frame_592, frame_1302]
BO_ 592 frame_592: 8 Vector__XXX
  SG_ checksum_33_8 : 39|8@0+ (1.0,0.0) [0.0|255.0] "" ECU
  SG_ sig_6_11 : 6|11@0+ (1.0000000000000005E-4,-0.03162277660168379) [-0.03162277660168379|0.17297722339831628] "W" ECU
  SG_ sig_7_1 : 7|1@0+ (1.0,0.0) [0.0|1.0] "" ECU
  SG_ sig_29_6 : 29|6@0- (1.0,0.0) [-32.0|30.0] "" ECU
  SG_ sig_8_3 : 8|3@1+ (1.0,0.0) [0.0|6.0] "" ECU
  SG_ sig_11_1 : 11|1@1+ (1.0,0.0) [0.0|1.0] "" ECU
  SG_ sig_30_1 : 30|1@0+ (1.0,0.0) [0.0|1.0] "" ECU
  SG_ sig_46_1 : 46|1@1+ (1.0,0.0) [0.0|1.0] "" ECU
  SG_ sig_45_1 : 45|1@1+ (1.0,0.0) [0.0|1.0] "" ECU
  SG_ sig_47_1 : 47|1@0+ (1.0,0.0) [0.0|1.0] "" ECU

BO_ 1813 frame_1813: 7 Vector__XXX
  SG_ checksum_1_8 : 7|8@0+ (1.0,0.0) [0.0|255.0] "" ECU
  SG_ sig_21_5 : 21|5@0- (1.0000000000000005E-4,0.0031622776601683794) [0.0015622776601683787|0.00456227766016838] "A" ECU
  SG_ sig_15_10 : 15|10@0+ (1.0000000000000005E-4,0.0) [0.0|0.10220000000000004] "kWh" ECU
  SG_ sig_16_11 : 16|11@0- (1.0,0.0) [-1024.0|1022.0] "" ECU
  SG_ sig_53_6 : 53|6@0+ (1.0000000000000006E-6,3.1622776601683795E-5) [3.1622776601683795E-5|9.362277660168383E-5] "kWh" ECU
  SG_ sig_54_1 : 54|1@0+ (1.0,0.0) [0.0|1.0] "" ECU

BO_ 1323 frame_1323: 7 Vector__XXX
  SG_ checksum_25_8 : 24|8@1+ (1.0,0.0) [0.0|255.0] "" ECU
  SG_ sig_3_15 : 3|15@1+ (1.0000000000000006E-6,0.03162277660168379) [0.03162277660168379|0.06438877660168381] "kWh" ECU
  SG_ sig_23_6 : 23|6@0- (1.0,0.0) [-32.0|30.0] "" ECU
  SG_ sig_41_9 : 41|9@1+ (0.0010000000000000002,-0.31622776601683794) [-0.31622776601683794|0.19377223398316218] "kWh" ECU
  SG_ sig_39_7 : 39|7@0- (1.0000000000000005E-4,0.0) [-0.006400000000000003|0.006200000000000002] "m/s^2" ECU
  SG_ sig_32_1 : 32|1@0+ (1.0,0.0) [0.0|1.0] "" ECU
  SG_ sig_40_7 : 40|7@0- (0.010000000000000002,-0.31622776601683794) [-0.9562277660168381|0.30377223398316217] "km/h" ECU

BO_ 334 frame_334: 4 Vector__XXX
  SG_ checksum_1_8 : 7|8@0+ (1.0,0.0) [0.0|255.0] "" ECU
  SG_ sig_20_9 : 20|9@0+ (100.0,0.0) [0.0|51000.0] "W" ECU
  SG_ sig_14_10 : 14|10@0- (10.0,-3162.2776601683795) [-8282.27766016838|1937.7223398316205] "V" ECU
  SG_ sig_15_1 : 15|1@0+ (1.0,0.0) [0.0|1.0] "" ECU
  SG_ sig_26_3 : 26|3@0+ (1.0,0.0) [0.0|6.0] "" ECU
  SG_ sig_27_1 : 27|1@0+ (1.0,0.0) [0.0|1.0] "" ECU

BO_ 18 frame_18: 3 Vector__XXX
  SG_ checksum_1_8 : 0|8@1+ (1.0,0.0) [0.0|255.0] "" ECU
  SG_ sig_13_10 : 13|10@1+ (1.0000000000000006E-6,0.0) [0.0|0.0010220000000000006] "kWh" ECU
  SG_ sig_9_4 : 9|4@1+ (1.0,0.0) [0.0|14.0] "" ECU
  SG_ sig_8_1 : 8|1@1+ (1.0,0.0) [0.0|1.0] "" ECU
  SG_ sig_23_1 : 23|1@1+ (1.0,0.0) [0.0|1.0] "" ECU

BO_ 793 frame_793: 7 ECU
  SG_ checksum_33_8 : 32|8@1+ (1.0,0.0) [0.0|255.0] "" Vector__XXX
  SG_ sig_8_17 : 8|17@0- (1.0,0.0) [-65536.0|65534.0] "" Vector__XXX
  SG_ sig_4_10 : 4|10@0+ (0.010000000000000002,-3.1622776601683795) [-3.1622776601683795|7.0577223398316224] "s" Vector__XXX
  SG_ sig_9_1 : 9|1@1+ (1.0,0.0) [0.0|1.0] "" Vector__XXX
  SG_ sig_43_12 : 43|12@0+ (1.0,0.0) [0.0|4094.0] "" Vector__XXX
  SG_ sig_47_2 : 47|2@0- (1.0,0.0) [-2.0|1.0] "" Vector__XXX
  SG_ sig_44_2 : 44|2@1- (1.0,0.0) [-2.0|1.0] "" Vector__XXX

BO_ 1302 frame_1302: 8 Vector__XXX
  SG_ checksum_57_8 : 63|8@0+ (1.0,0.0) [0.0|255.0] "" ECU
  SG_ sig_11_8 : 11|8@1- (1.0000000000000007E-7,0.0) [-1.280000000000001E-5|1.260000000000001E-5] "km/h" ECU
  SG_ sig_1_9 : 1|9@1+ (1.0,0.0) [0.0|510.0] "" ECU
  SG_ sig_10_1 : 10|1@0+ (1.0,0.0) [0.0|1.0] "" ECU
  SG_ sig_22_4 : 22|4@0- (1.0,0.0) [-8.0|6.0] "" ECU
  SG_ sig_41_14 : 41|14@1+ (1.0000000000000009E-9,0.0) [0.0|1.6382000000000014E-5] "V" ECU
  SG_ sig_28_8 : 28|8@1+ (100.0,3162.2776601683795) [3162.2776601683795|28562.27766016838] "V" ECU
  SG_ sig_24_4 : 24|4@1- (10000.0,31622.776601683792) [-48377.22339831621|91622.77660168378] "W" ECU
  SG_ sig_39_3 : 39|3@0- (1.0,0.0) [-4.0|2.0] "" ECU
  SG_ sig_40_1 : 40|1@1+ (1.0,0.0) [0.0|1.0] "" ECU
  SG_ sig_55_1 : 55|1@1+ (1.0,0.0) [0.0|1.0] "" ECU

BO_ 1622 frame_1622: 4 Vector__XXX
  SG_ checksum_25_8 : 24|8@1+ (1.0,0.0) [0.0|255.0] "" ECU
  SG_ sig_5_17 : 5|17@1- (1.0000000000000009E-9,3.1622776601683795E-5) [-3.391322339831626E-5|9.715677660168386E-5] "m/s^2" ECU
  SG_ sig_0_5 : 0|5@1- (1.0,0.0) [-16.0|14.0] "" ECU
  SG_ sig_22_2 : 22|2@1+ (1.0,0.0) [0.0|3.0] "" ECU

BO_ 465 frame_465: 3 ECU
  SG_ checksum_17_8 : 23|8@0+ (1.0,0.0) [0.0|255.0] "" Vector__XXX
  SG_ sig_7_13 : 7|13@0+ (1.0,0.0) [0.0|8190.0] "" Vector__XXX

BO_ 1997 frame_1997: 4 Vector__XXX
  SG_ checksum_9_8 : 8|8@1+ (1.0,0.0) [0.0|255.0] "" ECU
  SG_ sig_1_5 : 1|5@1- (1.0,0.0) [-16.0|14.0] "" ECU
  SG_ sig_7_2 : 7|2@0- (1.0,0.0) [-2.0|1.0] "" ECU
  SG_ sig_16_9 : 16|9@0+ (0.010000000000000002,-3.1622776601683795) [-3.1622776601683795|1.937722339831622] "V" ECU
  SG_ sig_23_6 : 23|6@0+ (1.0,0.0) [0.0|62.0] "" ECU
  SG_ sig_17_1 : 17|1@1+ (1.0,0.0) [0.0|1.0] "" ECU

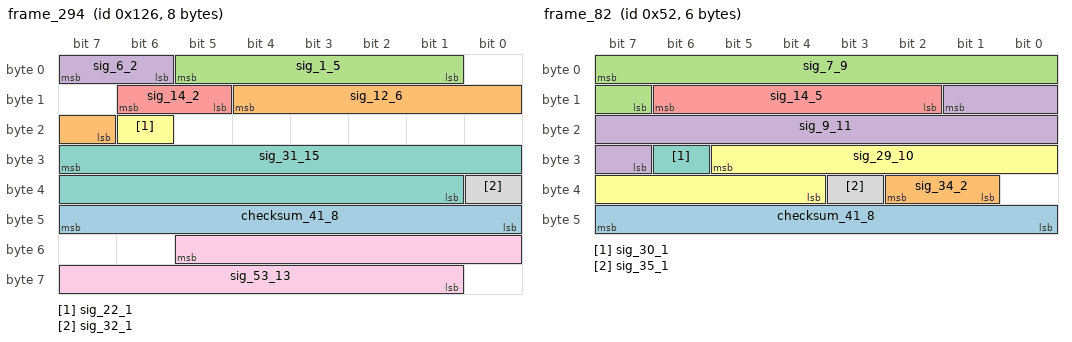
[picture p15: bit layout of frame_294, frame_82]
BO_ 294 frame_294: 8 ECU
  SG_ checksum_41_8 : 47|8@0+ (1.0,0.0) [0.0|255.0] "" Vector__XXX
  SG_ sig_12_6 : 12|6@0+ (1.0,0.0) [0.0|62.0] "" Vector__XXX
  SG_ sig_1_5 : 1|5@1+ (1.0,0.0) [0.0|30.0] "" Vector__XXX
  SG_ sig_6_2 : 6|2@1+ (1.0,0.0) [0.0|3.0] "" Vector__XXX
  SG_ sig_14_2 : 14|2@0- (1.0,0.0) [-2.0|1.0] "" Vector__XXX
  SG_ sig_22_1 : 22|1@1+ (1.0,0.0) [0.0|1.0] "" Vector__XXX
  SG_ sig_31_15 : 31|15@0- (1.0000000000000011E-10,3.162277660168379E-6) [1.5238776601683774E-6|4.800477660168381E-6] "A" Vector__XXX
  SG_ sig_32_1 : 32|1@1+ (1.0,0.0) [0.0|1.0] "" Vector__XXX
  SG_ sig_53_13 : 53|13@0- (1.0,0.0) [-4096.0|4094.0] "" Vector__XXX

BO_ 82 frame_82: 6 Vector__XXX
  SG_ checksum_41_8 : 47|8@0+ (1.0,0.0) [0.0|255.0] "" ECU
  SG_ sig_34_2 : 34|2@0+ (1.0,0.0) [0.0|3.0] "" ECU
  SG_ sig_7_9 : 7|9@0+ (1.0000000000000006E-6,0.0) [0.0|5.100000000000003E-4] "km/h" ECU
  SG_ sig_9_11 : 9|11@0+ (1.0000000000000006E-5,0.0031622776601683794) [0.0031622776601683794|0.023622277660168393] "V" ECU
  SG_ sig_14_5 : 14|5@0+ (0.0010000000000000002,-0.03162277660168379) [-0.03162277660168379|-0.0016227766016837855] "V" ECU
  SG_ sig_29_10 : 29|10@0+ (0.0010000000000000002,0.31622776601683794) [0.31622776601683794|1.3382277660168382] "km/h" ECU
  SG_ sig_30_1 : 30|1@0+ (1.0,0.0) [0.0|1.0] "" ECU
  SG_ sig_35_1 : 35|1@0+ (1.0,0.0) [0.0|1.0] "" ECU

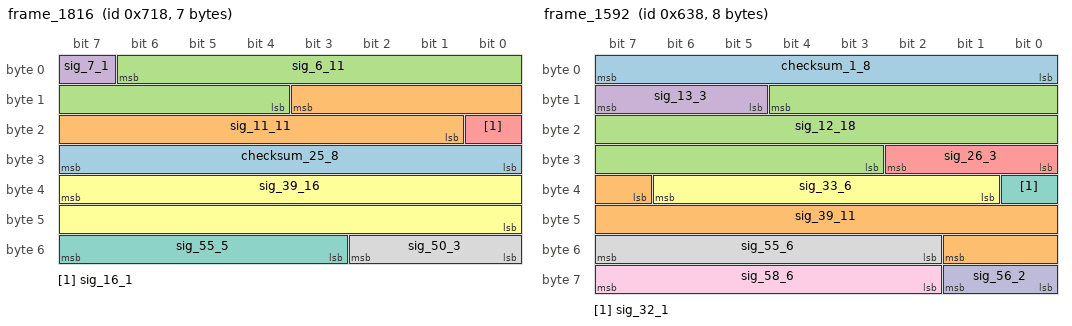
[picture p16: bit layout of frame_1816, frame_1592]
BO_ 1816 frame_1816: 7 Vector__XXX
  SG_ checksum_25_8 : 31|8@0+ (1.0,0.0) [0.0|255.0] "" ECU
  SG_ sig_11_11 : 11|11@0- (1.0,0.0) [-1024.0|1022.0] "" ECU
  SG_ sig_6_11 : 6|11@0+ (0.1,-31.622776601683793) [-31.622776601683793|172.97722339831623] "km/h" ECU
  SG_ sig_7_1 : 7|1@0+ (1.0,0.0) [0.0|1.0] "" ECU
  SG_ sig_16_1 : 16|1@0+ (1.0,0.0) [0.0|1.0] "" ECU
  SG_ sig_39_16 : 39|16@0- (1.0,0.0) [-32768.0|32766.0] "" ECU
  SG_ sig_55_5 : 55|5@0- (0.1,0.0) [-1.6|1.4000000000000001] "m/s^2" ECU
  SG_ sig_50_3 : 50|3@0- (1.0,0.0) [-4.0|2.0] "" ECU

BO_ 159 frame_159: 7 Vector__XXX
  SG_ checksum_1_8 : 7|8@0+ (1.0,0.0) [0.0|255.0] "" ECU
  SG_ sig_21_15 : 21|15@1+ (1.0000000000000007E-7,0.0) [0.0|0.0032766000000000023] "V" ECU
  SG_ sig_8_13 : 8|13@1+ (1.0,0.0) [0.0|8190.0] "" ECU
  SG_ sig_39_4 : 39|4@0- (0.010000000000000002,0.0) [-0.08000000000000002|0.06000000000000001] "W" ECU
  SG_ sig_46_15 : 46|15@0- (1.0,0.0) [-16384.0|16382.0] "" ECU
  SG_ sig_47_1 : 47|1@1+ (1.0,0.0) [0.0|1.0] "" ECU

BO_ 1449 frame_1449: 3 Vector__XXX
  SG_ checksum_9_8 : 15|8@0+ (1.0,0.0) [0.0|255.0] "" ECU
  SG_ sig_0_8 : 0|8@1+ (1.0,0.0) [0.0|254.0] "" ECU
  SG_ sig_16_3 : 16|3@1- (1.0,0.0) [-4.0|2.0] "" ECU
  SG_ sig_21_3 : 21|3@1+ (1.0,0.0) [0.0|6.0] "" ECU

BO_ 1177 frame_1177: 7 Vector__XXX
  SG_ checksum_41_8 : 40|8@1+ (1.0,0.0) [0.0|255.0] "" ECU
  SG_ sig_22_2 : 22|2@1- (1.0,0.0) [-2.0|1.0] "" ECU
  SG_ sig_2_14 : 2|14@1+ (1.0000000000000008E-8,0.0) [0.0|1.6382000000000015E-4] "A" ECU
  SG_ sig_1_2 : 1|2@0- (1.0,0.0) [-2.0|1.0] "" ECU
  SG_ sig_16_6 : 16|6@1+ (1.0000000000000006E-6,3.1622776601683795E-5) [3.1622776601683795E-5|9.362277660168383E-5] "A" ECU
  SG_ sig_25_15 : 25|15@1- (1.0,-31622.776601683792) [-48006.77660168379|-15240.776601683792] "m/s^2" ECU
  SG_ sig_48_8 : 48|8@1- (0.1,0.0) [-12.8|12.600000000000001] "V" ECU

BO_ 1356 frame_1356: 3 Vector__XXX
  SG_ checksum_17_8 : 23|8@0+ (1.0,0.0) [0.0|255.0] "" ECU
  SG_ sig_1_13 : 1|13@1- (1.0000000000000006E-6,0.0031622776601683794) [-9.33722339831623E-4|0.007256277660168382] "V" ECU
  SG_ sig_0_1 : 0|1@1+ (1.0,0.0) [0.0|1.0] "" ECU
  SG_ sig_14_2 : 14|2@1+ (1.0,0.0) [0.0|3.0] "" ECU

BO_ 875 frame_875: 4 Vector__XXX
  SG_ checksum_25_8 : 31|8@0+ (1.0,0.0) [0.0|255.0] "" ECU
  SG_ sig_7_10 : 7|10@1+ (1.0,0.0) [0.0|1022.0] "" ECU
  SG_ sig_6_5 : 6|5@0+ (1.0000000000000006E-5,3.1622776601683794E-4) [3.1622776601683794E-4|6.162277660168381E-4] "W" ECU
  SG_ sig_0_2 : 0|2@1+ (1.0,0.0) [0.0|3.0] "" ECU
  SG_ sig_18_6 : 18|6@1+ (0.0010000000000000002,0.0) [0.0|0.06200000000000001] "km/h" ECU

BO_ 593 frame_593: 5 ECU
  SG_ checksum_33_8 : 39|8@0+ (1.0,0.0) [0.0|255.0] "" Vector__XXX
  SG_ sig_9_3 : 9|3@0+ (1.0,0.0) [0.0|6.0] "" Vector__XXX
  SG_ sig_0_7 : 0|7@0+ (100.0,3162.2776601683795) [3162.2776601683795|15762.27766016838] "m/s^2" Vector__XXX
  SG_ sig_5_5 : 5|5@0+ (1.0000000000000007E-7,0.0) [0.0|3.000000000000002E-6] "kWh" Vector__XXX
  SG_ sig_7_2 : 7|2@0+ (1.0,0.0) [0.0|3.0] "" Vector__XXX

BO_ 1592 frame_1592: 8 Vector__XXX
  SG_ checksum_1_8 : 7|8@0+ (1.0,0.0) [0.0|255.0] "" ECU
  SG_ sig_39_11 : 39|11@1+ (1.0000000000000006E-6,0.0) [0.0|0.0020460000000000014] "m/s^2" ECU
  SG_ sig_12_18 : 12|18@0- (1.0000000000000005E-4,-3.1622776601683795) [-16.269477660168384|9.944722339831626] "A" ECU
  SG_ sig_13_3 : 13|3@1+ (1.0,0.0) [0.0|6.0] "" ECU
  SG_ sig_26_3 : 26|3@0- (1.0,0.0) [-4.0|2.0] "" ECU
  SG_ sig_33_6 : 33|6@1+ (100.0,3162.2776601683795) [3162.2776601683795|9362.27766016838] "kWh" ECU
  SG_ sig_32_1 : 32|1@1+ (1.0,0.0) [0.0|1.0] "" ECU
  SG_ sig_55_6 : 55|6@0+ (0.1,-3.1622776601683795) [-3.1622776601683795|3.0377223398316207] "s" ECU
  SG_ sig_58_6 : 58|6@1+ (1.0,0.0) [0.0|62.0] "" ECU
  SG_ sig_56_2 : 56|2@1- (1.0,0.0) [-2.0|1.0] "" ECU

BO_ 1870 frame_1870: 7 Vector__XXX
  SG_ checksum_33_8 : 32|8@1+ (1.0,0.0) [0.0|255.0] "" ECU
  SG_ sig_21_11 : 21|11@1+ (1.0,0.0) [0.0|2046.0] "" ECU
  SG_ sig_1_19 : 1|19@1+ (0.010000000000000002,3162.2776601683795) [3162.2776601683795|8405.13766016838] "A" ECU
  SG_ sig_0_1 : 0|1@1+ (1.0,0.0) [0.0|1.0] "" ECU
  SG_ sig_20_1 : 20|1@1+ (1.0,0.0) [0.0|1.0] "" ECU
  SG_ sig_40_15 : 40|15@1- (1.0,-31622.776601683792) [-48006.77660168379|-15240.776601683792] "km/h" ECU
  SG_ sig_55_1 : 55|1@1+ (1.0,0.0) [0.0|1.0] "" ECU

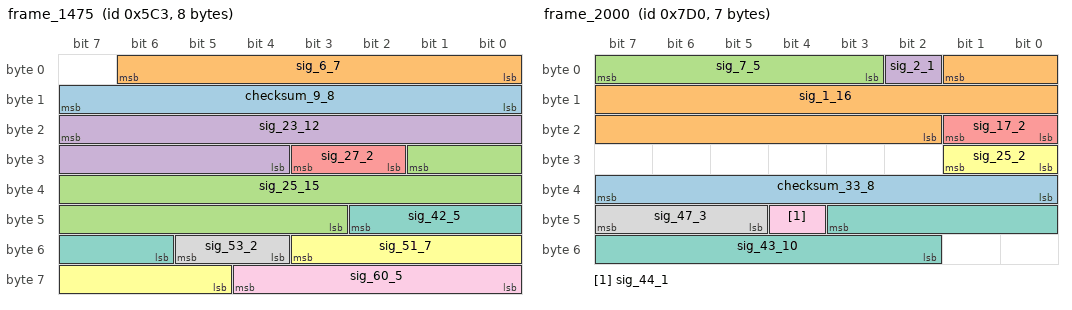
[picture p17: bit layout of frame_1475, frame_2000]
BO_ 1475 frame_1475: 8 ECU
  SG_ checksum_9_8 : 15|8@0+ (1.0,0.0) [0.0|255.0] "" Vector__XXX
  SG_ sig_6_7 : 6|7@0- (1.0,0.0) [-64.0|62.0] "kWh" Vector__XXX
  SG_ sig_25_15 : 25|15@0- (1.0000000000000011E-10,3.162277660168379E-6) [1.5238776601683774E-6|4.800477660168381E-6] "kWh" Vector__XXX
  SG_ sig_23_12 : 23|12@0+ (0.010000000000000002,0.0) [0.0|40.940000000000005] "V" Vector__XXX
  SG_ sig_27_2 : 27|2@0+ (1.0,0.0) [0.0|3.0] "" Vector__XXX
  SG_ sig_51_7 : 51|7@0+ (0.010000000000000002,0.0) [0.0|1.2600000000000002] "V" Vector__XXX
  SG_ sig_42_5 : 42|5@0- (0.0010000000000000002,0.0) [-0.016000000000000004|0.014000000000000004] "s" Vector__XXX
  SG_ sig_53_2 : 53|2@0- (1.0,0.0) [-2.0|1.0] "" Vector__XXX
  SG_ sig_60_5 : 60|5@0- (1.0000000000000005E-4,0.0031622776601683794) [0.0015622776601683787|0.00456227766016838] "V" Vector__XXX

BO_ 440 frame_440: 3 Vector__XXX
  SG_ checksum_9_8 : 15|8@0+ (1.0,0.0) [0.0|255.0] "" ECU
  SG_ sig_7_5 : 7|5@0- (0.010000000000000002,0.31622776601683794) [0.1562277660168379|0.45622776601683795] "km/h" ECU
  SG_ sig_16_7 : 16|7@1+ (1.0000000000000005E-4,0.0031622776601683794) [0.0031622776601683794|0.015762277660168383] "s" ECU
  SG_ sig_23_1 : 23|1@0+ (1.0,0.0) [0.0|1.0] "" ECU

BO_ 1080 frame_1080: 8 Vector__XXX
  SG_ checksum_57_8 : 63|8@0+ (1.0,0.0) [0.0|255.0] "" ECU
  SG_ sig_31_24 : 31|24@0+ (1.0000000000000011E-10,0.0) [0.0|0.0016777214000000017] "km/h" ECU
  SG_ sig_22_7 : 22|7@0- (0.010000000000000002,0.0) [-0.6400000000000001|0.6200000000000001] "s" ECU
  SG_ sig_6_16 : 6|16@0+ (0.1,-3162.2776601683795) [-3162.2776601683795|3391.122339831621] "s" ECU
  SG_ sig_55_8 : 55|8@0- (1.0,0.0) [-128.0|126.0] "" ECU

BO_ 2000 frame_2000: 7 Vector__XXX
  SG_ checksum_33_8 : 39|8@0+ (1.0,0.0) [0.0|255.0] "" ECU
  SG_ sig_1_16 : 1|16@0- (0.0010000000000000002,-31.622776601683793) [-64.3907766016838|1.1432233983162128] "V" ECU
  SG_ sig_7_5 : 7|5@0+ (1.0,0.0) [0.0|30.0] "" ECU
  SG_ sig_2_1 : 2|1@0+ (1.0,0.0) [0.0|1.0] "" ECU
  SG_ sig_17_2 : 17|2@0+ (1.0,0.0) [0.0|3.0] "" ECU
  SG_ sig_25_2 : 25|2@0- (1.0,0.0) [-2.0|1.0] "" ECU
  SG_ sig_43_10 : 43|10@0- (0.1,31.622776601683793) [-19.57722339831621|82.6227766016838] "V" ECU
  SG_ sig_47_3 : 47|3@0- (1.0,0.0) [-4.0|2.0] "" ECU
  SG_ sig_44_1 : 44|1@0+ (1.0,0.0) [0.0|1.0] "" ECU

BO_ 192 frame_192: 6 ECU
  SG_ checksum_1_8 : 0|8@1+ (1.0,0.0) [0.0|255.0] "" Vector__XXX
  SG_ sig_10_31 : 10|31@1+ (1.0000000000000014E-13,3.1622776601683795E-5) [3.1622776601683795E-5|2.463711412016841E-4] "A" Vector__XXX
  SG_ sig_9_2 : 9|2@0+ (1.0,0.0) [0.0|3.0] "" Vector__XXX
  SG_ sig_47_7 : 47|7@0- (1.0000000000000005E-4,-0.0031622776601683794) [-0.009562277660168383|0.003037722339831623] "W" Vector__XXX

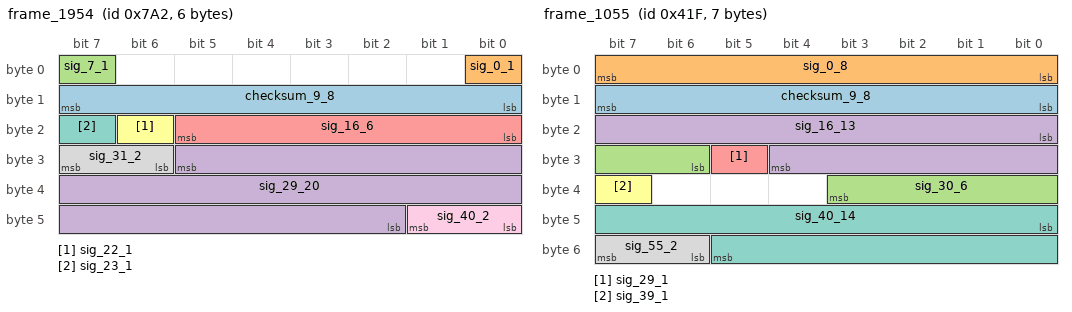
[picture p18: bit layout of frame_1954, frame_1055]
BO_ 1954 frame_1954: 6 ECU
  SG_ checksum_9_8 : 8|8@1+ (1.0,0.0) [0.0|255.0] "" Vector__XXX
  SG_ sig_0_1 : 0|1@1+ (1.0,0.0) [0.0|1.0] "" Vector__XXX
  SG_ sig_7_1 : 7|1@1+ (1.0,0.0) [0.0|1.0] "" Vector__XXX
  SG_ sig_29_20 : 29|20@0+ (1.0,0.0) [0.0|1048574.0] "" Vector__XXX
  SG_ sig_16_6 : 16|6@1+ (1.0,0.0) [0.0|62.0] "" Vector__XXX
  SG_ sig_22_1 : 22|1@0+ (1.0,0.0) [0.0|1.0] "" Vector__XXX
  SG_ sig_23_1 : 23|1@0+ (1.0,0.0) [0.0|1.0] "" Vector__XXX
  SG_ sig_31_2 : 31|2@0- (1.0,0.0) [-2.0|1.0] "" Vector__XXX
  SG_ sig_40_2 : 40|2@1+ (1.0,0.0) [0.0|3.0] "" Vector__XXX

BO_ 1055 frame_1055: 7 Vector__XXX
  SG_ checksum_9_8 : 8|8@1+ (1.0,0.0) [0.0|255.0] "" ECU
  SG_ sig_0_8 : 0|8@1- (1.0,0.0) [-128.0|126.0] "" ECU
  SG_ sig_30_6 : 30|6@1- (1.0,-31.622776601683793) [-63.622776601683796|-1.6227766016837926] "A" ECU
  SG_ sig_16_13 : 16|13@1+ (0.1,-316.22776601683796) [-316.22776601683796|502.77223398316204] "kWh" ECU
  SG_ sig_29_1 : 29|1@1+ (1.0,0.0) [0.0|1.0] "" ECU
  SG_ sig_39_1 : 39|1@0+ (1.0,0.0) [0.0|1.0] "" ECU
  SG_ sig_40_14 : 40|14@1+ (1.0000000000000009E-9,0.0) [0.0|1.6382000000000014E-5] "W" ECU
  SG_ sig_55_2 : 55|2@0- (1.0,0.0) [-2.0|1.0] "" ECU

BO_ 1993 frame_1993: 8 ECU
  SG_ checksum_57_8 : 63|8@0+ (1.0,0.0) [0.0|255.0] "" Vector__XXX
  SG_ sig_37_13 : 37|13@0+ (1.0000000000000006E-6,0.0031622776601683794) [0.0031622776601683794|0.011352277660168384] "W" Vector__XXX
  SG_ sig_3_24 : 3|24@1- (1.000000000000001E-11,0.0) [-8.388608000000009E-5|8.388606000000009E-5] "A" Vector__XXX
  SG_ sig_0_3 : 0|3@1+ (1.0,0.0) [0.0|6.0] "" Vector__XXX
  SG_ sig_27_5 : 27|5@1- (1.0,0.0) [-16.0|14.0] "" Vector__XXX
  SG_ sig_39_2 : 39|2@0+ (1.0,0.0) [0.0|3.0] "" Vector__XXX
  SG_ sig_55_8 : 55|8@0- (1.0,0.0) [-128.0|126.0] "" Vector__XXX

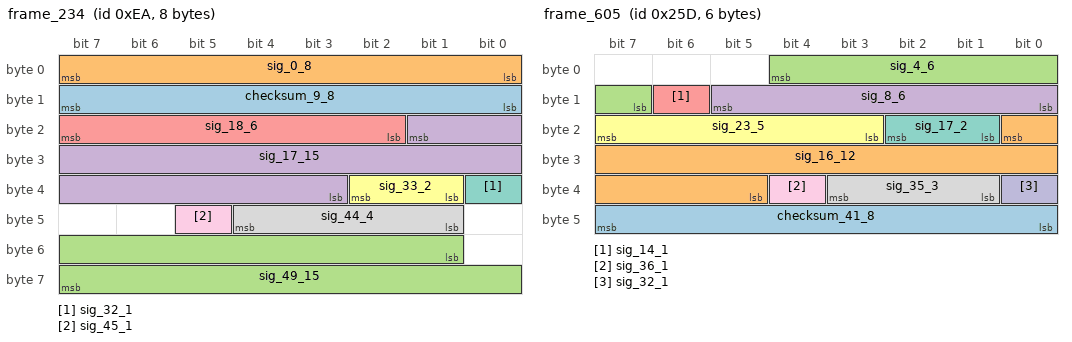
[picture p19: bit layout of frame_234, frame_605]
BO_ 234 frame_234: 8 Vector__XXX
  SG_ checksum_9_8 : 8|8@1+ (1.0,0.0) [0.0|255.0] "" ECU
  SG_ sig_0_8 : 0|8@1+ (100.0,-3162.2776601683795) [-3162.2776601683795|22237.72233983162] "m/s^2" ECU
  SG_ sig_49_15 : 49|15@1+ (1.0000000000000007E-7,-0.0031622776601683794) [-0.0031622776601683794|1.1432233983162295E-4] "W" ECU
  SG_ sig_17_15 : 17|15@0+ (1.0,0.0) [0.0|32766.0] "" ECU
  SG_ sig_18_6 : 18|6@1+ (100.0,3162.2776601683795) [3162.2776601683795|9362.27766016838] "V" ECU
  SG_ sig_33_2 : 33|2@1+ (1.0,0.0) [0.0|3.0] "" ECU
  SG_ sig_32_1 : 32|1@1+ (1.0,0.0) [0.0|1.0] "" ECU
  SG_ sig_44_4 : 44|4@0- (1.0000000000000005E-4,-3.1622776601683794E-4) [-0.0011162277660168383|2.8377223398316233E-4] "s" ECU
  SG_ sig_45_1 : 45|1@0+ (1.0,0.0) [0.0|1.0] "" ECU

BO_ 1075 frame_1075: 7 Vector__XXX
  SG_ checksum_9_8 : 15|8@0+ (1.0,0.0) [0.0|255.0] "" ECU
  SG_ sig_0_8 : 0|8@1- (1.0000000000000007E-7,-3.162277660168379E-6) [-1.596227766016839E-5|9.43772233983163E-6] "V" ECU
  SG_ sig_26_15 : 26|15@1+ (1.0000000000000006E-6,-0.03162277660168379) [-0.03162277660168379|0.001143223398316226] "m/s^2" ECU
  SG_ sig_22_7 : 22|7@0- (10.0,-316.22776601683796) [-956.2277660168379|303.77223398316204] "V" ECU
  SG_ sig_23_3 : 23|3@1+ (1.0,0.0) [0.0|6.0] "" ECU
  SG_ sig_42_14 : 42|14@1- (10.0,-31622.776601683792) [-113542.77660168378|50277.22339831621] "W" ECU

BO_ 845 frame_845: 6 Vector__XXX
  SG_ checksum_17_8 : 23|8@0+ (1.0,0.0) [0.0|255.0] "" ECU
  SG_ sig_0_15 : 0|15@1- (1.0000000000000006E-6,0.0) [-0.01638400000000001|0.01638200000000001] "A" ECU
  SG_ sig_25_15 : 25|15@1- (1.0000000000000006E-5,0.31622776601683794) [0.15238776601683784|0.4800477660168381] "kWh" ECU
  SG_ sig_24_1 : 24|1@0+ (1.0,0.0) [0.0|1.0] "" ECU
  SG_ sig_47_6 : 47|6@0- (0.1,0.0) [-3.2|3.0] "V" ECU

BO_ 605 frame_605: 6 Vector__XXX
  SG_ checksum_41_8 : 47|8@0+ (1.0,0.0) [0.0|255.0] "" ECU
  SG_ sig_16_12 : 16|12@0+ (10.0,0.0) [0.0|40940.0] "s" ECU
  SG_ sig_4_6 : 4|6@0+ (1000.0,-31622.776601683792) [-31622.776601683792|30377.223398316208] "km/h" ECU
  SG_ sig_8_6 : 8|6@1- (0.1,3.1622776601683795) [-0.037722339831620655|6.16227766016838] "m/s^2" ECU
  SG_ sig_14_1 : 14|1@1+ (1.0,0.0) [0.0|1.0] "" ECU
  SG_ sig_23_5 : 23|5@0- (1.0000000000000007E-7,-3.162277660168379E-6) [-4.762277660168381E-6|-1.7622776601683782E-6] "m/s^2" ECU
  SG_ sig_17_2 : 17|2@1- (1.0,0.0) [-2.0|1.0] "" ECU
  SG_ sig_35_3 : 35|3@0+ (1.0,0.0) [0.0|6.0] "" ECU
  SG_ sig_36_1 : 36|1@0+ (1.0,0.0) [0.0|1.0] "" ECU
  SG_ sig_32_1 : 32|1@0+ (1.0,0.0) [0.0|1.0] "" ECU

BO_ 1330 frame_1330: 4 Vector__XXX
  SG_ checksum_9_8 : 15|8@0+ (1.0,0.0) [0.0|255.0] "" ECU
  SG_ sig_4_5 : 4|5@0+ (0.1,3.1622776601683795) [3.1622776601683795|6.16227766016838] "kWh" ECU
  SG_ sig_7_2 : 7|2@0- (1.0,0.0) [-2.0|1.0] "" ECU
  SG_ sig_21_12 : 21|12@0+ (1.0000000000000006E-5,-0.03162277660168379) [-0.03162277660168379|0.009317223398316234] "A" ECU
  SG_ sig_23_2 : 23|2@0+ (1.0,0.0) [0.0|3.0] "" ECU
  SG_ sig_25_2 : 25|2@0- (1.0,0.0) [-2.0|1.0] "" ECU

CM_ BO_ 782 "Randomly defined CAN frame";
CM_ SG_ 782 checksum_17_8 "8 Bit checksum for protection of frame contents";
CM_ BO_ 1125 "Randomly defined CAN frame";
CM_ SG_ 1125 checksum_25_8 "8 Bit checksum for protection of frame contents";
CM_ BO_ 1842 "Randomly defined CAN frame";
CM_ SG_ 1842 checksum_41_8 "8 Bit checksum for protection of frame contents";
CM_ BO_ 1429 "Randomly defined CAN frame";
CM_ SG_ 1429 checksum_17_8 "8 Bit checksum for protection of frame contents";
CM_ BO_ 191 "Randomly defined CAN frame";
CM_ SG_ 191 checksum_33_8 "8 Bit checksum for protection of frame contents";
CM_ BO_ 1867 "Randomly defined CAN frame";
CM_ SG_ 1867 checksum_1_8 "8 Bit checksum for protection of frame contents";
CM_ BO_ 967 "Randomly defined CAN frame";
CM_ SG_ 967 checksum_17_8 "8 Bit checksum for protection of frame contents";
CM_ BO_ 61 "Randomly defined CAN frame";
CM_ SG_ 61 checksum_17_8 "8 Bit checksum for protection of frame contents";
CM_ BO_ 1403 "Randomly defined CAN frame";
CM_ SG_ 1403 checksum_41_8 "8 Bit checksum for protection of frame contents";
CM_ BO_ 1948 "Randomly defined CAN frame";
CM_ SG_ 1948 checksum_9_8 "8 Bit checksum for protection of frame contents";
CM_ BO_ 462 "Randomly defined CAN frame";
CM_ SG_ 462 checksum_17_8 "8 Bit checksum for protection of frame contents";
CM_ BO_ 158 "Randomly defined CAN frame";
CM_ SG_ 158 checksum_49_8 "8 Bit checksum for protection of frame contents";
CM_ BO_ 673 "Randomly defined CAN frame";
CM_ SG_ 673 checksum_25_8 "8 Bit checksum for protection of frame contents";
CM_ BO_ 422 "Randomly defined CAN frame";
CM_ SG_ 422 checksum_25_8 "8 Bit checksum for protection of frame contents";
CM_ BO_ 1821 "Randomly defined CAN frame";
CM_ SG_ 1821 checksum_1_8 "8 Bit checksum for protection of frame contents";
CM_ BO_ 1052 "Randomly defined CAN frame";
CM_ SG_ 1052 checksum_9_8 "8 Bit checksum for protection of frame contents";
CM_ BO_ 1380 "Randomly defined CAN frame";
CM_ SG_ 1380 checksum_9_8 "8 Bit checksum for protection of frame contents";
CM_ BO_ 1788 "Randomly defined CAN frame";
CM_ SG_ 1788 checksum_1_8 "8 Bit checksum for protection of frame contents";
CM_ BO_ 255 "Randomly defined CAN frame";
CM_ SG_ 255 checksum_1_8 "8 Bit checksum for protection of frame contents";
CM_ BO_ 586 "Randomly defined CAN frame";
CM_ SG_ 586 checksum_17_8 "8 Bit checksum for protection of frame contents";
CM_ BO_ 914 "Randomly defined CAN frame";
CM_ SG_ 914 checksum_33_8 "8 Bit checksum for protection of frame contents";
CM_ BO_ 565 "Randomly defined CAN frame";
CM_ SG_ 565 checksum_33_8 "8 Bit checksum for protection of frame contents";
CM_ BO_ 53 "Randomly defined CAN frame";
CM_ SG_ 53 checksum_1_8 "8 Bit checksum for protection of frame contents";
CM_ BO_ 752 "Randomly defined CAN frame";
CM_ SG_ 752 checksum_9_8 "8 Bit checksum for protection of frame contents";
CM_ BO_ 1312 "Randomly defined CAN frame";
CM_ SG_ 1312 checksum_25_8 "8 Bit checksum for protection of frame contents";
CM_ BO_ 863 "Randomly defined CAN frame";
CM_ SG_ 863 checksum_9_8 "8 Bit checksum for protection of frame contents";
CM_ BO_ 1297 "Randomly defined CAN frame";
CM_ SG_ 1297 checksum_17_8 "8 Bit checksum for protection of frame contents";
CM_ BO_ 1535 "Randomly defined CAN frame";
CM_ SG_ 1535 checksum_17_8 "8 Bit checksum for protection of frame contents";
CM_ BO_ 1829 "Randomly defined CAN frame";
CM_ SG_ 1829 checksum_57_8 "8 Bit checksum for protection of frame contents";
CM_ BO_ 262 "Randomly defined CAN frame";
CM_ SG_ 262 checksum_1_8 "8 Bit checksum for protection of frame contents";
CM_ BO_ 1208 "Randomly defined CAN frame";
CM_ SG_ 1208 checksum_25_8 "8 Bit checksum for protection of frame contents";
CM_ BO_ 1542 "Randomly defined CAN frame";
CM_ SG_ 1542 checksum_25_8 "8 Bit checksum for protection of frame contents";
CM_ BO_ 1341 "Randomly defined CAN frame";
CM_ SG_ 1341 checksum_41_8 "8 Bit checksum for protection of frame contents";
CM_ BO_ 1281 "Randomly defined CAN frame";
CM_ SG_ 1281 checksum_1_8 "8 Bit checksum for protection of frame contents";
CM_ BO_ 1119 "Randomly defined CAN frame";
CM_ SG_ 1119 checksum_1_8 "8 Bit checksum for protection of frame contents";
CM_ BO_ 869 "Randomly defined CAN frame";
CM_ SG_ 869 checksum_1_8 "8 Bit checksum for protection of frame contents";
CM_ BO_ 1381 "Randomly defined CAN frame";
CM_ SG_ 1381 checksum_57_8 "8 Bit checksum for protection of frame contents";
CM_ BO_ 678 "Randomly defined CAN frame";
CM_ SG_ 678 checksum_1_8 "8 Bit checksum for protection of frame contents";
CM_ BO_ 1157 "Randomly defined CAN frame";
CM_ SG_ 1157 checksum_9_8 "8 Bit checksum for protection of frame contents";
CM_ BO_ 152 "Randomly defined CAN frame";
CM_ SG_ 152 checksum_17_8 "8 Bit checksum for protection of frame contents";
CM_ BO_ 1496 "Randomly defined CAN frame";
CM_ SG_ 1496 checksum_33_8 "8 Bit checksum for protection of frame contents";
CM_ BO_ 111 "Randomly defined CAN frame";
CM_ SG_ 111 checksum_41_8 "8 Bit checksum for protection of frame contents";
CM_ BO_ 1237 "Randomly defined CAN frame";
CM_ SG_ 1237 checksum_25_8 "8 Bit checksum for protection of frame contents";
CM_ BO_ 509 "Randomly defined CAN frame";
CM_ SG_ 509 checksum_9_8 "8 Bit checksum for protection of frame contents";
CM_ BO_ 927 "Randomly defined CAN frame";
CM_ SG_ 927 checksum_1_8 "8 Bit checksum for protection of frame contents";
CM_ BO_ 199 "Randomly defined CAN frame";
CM_ SG_ 199 checksum_17_8 "8 Bit checksum for protection of frame contents";
CM_ BO_ 1601 "Randomly defined CAN frame";
CM_ SG_ 1601 checksum_1_8 "8 Bit checksum for protection of frame contents";
CM_ BO_ 1931 "Randomly defined CAN frame";
CM_ SG_ 1931 checksum_25_8 "8 Bit checksum for protection of frame contents";
CM_ BO_ 405 "Randomly defined CAN frame";
CM_ SG_ 405 checksum_9_8 "8 Bit checksum for protection of frame contents";
CM_ BO_ 1219 "Randomly defined CAN frame";
CM_ SG_ 1219 checksum_33_8 "8 Bit checksum for protection of frame contents";
CM_ BO_ 788 "Randomly defined CAN frame";
CM_ SG_ 788 checksum_17_8 "8 Bit checksum for protection of frame contents";
CM_ BO_ 1689 "Randomly defined CAN frame";
CM_ SG_ 1689 checksum_1_8 "8 Bit checksum for protection of frame contents";
CM_ BO_ 42 "Randomly defined CAN frame";
CM_ SG_ 42 checksum_17_8 "8 Bit checksum for protection of frame contents";
CM_ BO_ 1671 "Randomly defined CAN frame";
CM_ SG_ 1671 checksum_57_8 "8 Bit checksum for protection of frame contents";
CM_ BO_ 1890 "Randomly defined CAN frame";
CM_ SG_ 1890 checksum_17_8 "8 Bit checksum for protection of frame contents";
CM_ BO_ 434 "Randomly defined CAN frame";
CM_ SG_ 434 checksum_57_8 "8 Bit checksum for protection of frame contents";
CM_ BO_ 1389 "Randomly defined CAN frame";
CM_ SG_ 1389 checksum_9_8 "8 Bit checksum for protection of frame contents";
CM_ BO_ 141 "Randomly defined CAN frame";
CM_ SG_ 141 checksum_1_8 "8 Bit checksum for protection of frame contents";
CM_ BO_ 1524 "Randomly defined CAN frame";
CM_ SG_ 1524 checksum_9_8 "8 Bit checksum for protection of frame contents";
CM_ BO_ 924 "Randomly defined CAN frame";
CM_ SG_ 924 checksum_17_8 "8 Bit checksum for protection of frame contents";
CM_ BO_ 1022 "Randomly defined CAN frame";
CM_ SG_ 1022 checksum_41_8 "8 Bit checksum for protection of frame contents";
CM_ BO_ 412 "Randomly defined CAN frame";
CM_ SG_ 412 checksum_1_8 "8 Bit checksum for protection of frame contents";
CM_ BO_ 592 "Randomly defined CAN frame";
CM_ SG_ 592 checksum_33_8 "8 Bit checksum for protection of frame contents";
CM_ BO_ 1813 "Randomly defined CAN frame";
CM_ SG_ 1813 checksum_1_8 "8 Bit checksum for protection of frame contents";
CM_ BO_ 1323 "Randomly defined CAN frame";
CM_ SG_ 1323 checksum_25_8 "8 Bit checksum for protection of frame contents";
CM_ BO_ 334 "Randomly defined CAN frame";
CM_ SG_ 334 checksum_1_8 "8 Bit checksum for protection of frame contents";
CM_ BO_ 18 "Randomly defined CAN frame";
CM_ SG_ 18 checksum_1_8 "8 Bit checksum for protection of frame contents";
CM_ BO_ 793 "Randomly defined CAN frame";
CM_ SG_ 793 checksum_33_8 "8 Bit checksum for protection of frame contents";
CM_ BO_ 1302 "Randomly defined CAN frame";
CM_ SG_ 1302 checksum_57_8 "8 Bit checksum for protection of frame contents";
CM_ BO_ 1622 "Randomly defined CAN frame";
CM_ SG_ 1622 checksum_25_8 "8 Bit checksum for protection of frame contents";
CM_ BO_ 465 "Randomly defined CAN frame";
CM_ SG_ 465 checksum_17_8 "8 Bit checksum for protection of frame contents";
CM_ BO_ 1997 "Randomly defined CAN frame";
CM_ SG_ 1997 checksum_9_8 "8 Bit checksum for protection of frame contents";
CM_ BO_ 294 "Randomly defined CAN frame";
CM_ SG_ 294 checksum_41_8 "8 Bit checksum for protection of frame contents";
CM_ BO_ 82 "Randomly defined CAN frame";
CM_ SG_ 82 checksum_41_8 "8 Bit checksum for protection of frame contents";
CM_ BO_ 1816 "Randomly defined CAN frame";
CM_ SG_ 1816 checksum_25_8 "8 Bit checksum for protection of frame contents";
CM_ BO_ 159 "Randomly defined CAN frame";
CM_ SG_ 159 checksum_1_8 "8 Bit checksum for protection of frame contents";
CM_ BO_ 1449 "Randomly defined CAN frame";
CM_ SG_ 1449 checksum_9_8 "8 Bit checksum for protection of frame contents";
CM_ BO_ 1177 "Randomly defined CAN frame";
CM_ SG_ 1177 checksum_41_8 "8 Bit checksum for protection of frame contents";
CM_ BO_ 1356 "Randomly defined CAN frame";
CM_ SG_ 1356 checksum_17_8 "8 Bit checksum for protection of frame contents";
CM_ BO_ 875 "Randomly defined CAN frame";
CM_ SG_ 875 checksum_25_8 "8 Bit checksum for protection of frame contents";
CM_ BO_ 593 "Randomly defined CAN frame";
CM_ SG_ 593 checksum_33_8 "8 Bit checksum for protection of frame contents";
CM_ BO_ 1592 "Randomly defined CAN frame";
CM_ SG_ 1592 checksum_1_8 "8 Bit checksum for protection of frame contents";
CM_ BO_ 1870 "Randomly defined CAN frame";
CM_ SG_ 1870 checksum_33_8 "8 Bit checksum for protection of frame contents";
CM_ BO_ 1475 "Randomly defined CAN frame";
CM_ SG_ 1475 checksum_9_8 "8 Bit checksum for protection of frame contents";
CM_ BO_ 440 "Randomly defined CAN frame";
CM_ SG_ 440 checksum_9_8 "8 Bit checksum for protection of frame contents";
CM_ BO_ 1080 "Randomly defined CAN frame";
CM_ SG_ 1080 checksum_57_8 "8 Bit checksum for protection of frame contents";
CM_ BO_ 2000 "Randomly defined CAN frame";
CM_ SG_ 2000 checksum_33_8 "8 Bit checksum for protection of frame contents";
CM_ BO_ 192 "Randomly defined CAN frame";
CM_ SG_ 192 checksum_1_8 "8 Bit checksum for protection of frame contents";
CM_ BO_ 1954 "Randomly defined CAN frame";
CM_ SG_ 1954 checksum_9_8 "8 Bit checksum for protection of frame contents";
CM_ BO_ 1055 "Randomly defined CAN frame";
CM_ SG_ 1055 checksum_9_8 "8 Bit checksum for protection of frame contents";
CM_ BO_ 1993 "Randomly defined CAN frame";
CM_ SG_ 1993 checksum_57_8 "8 Bit checksum for protection of frame contents";
CM_ BO_ 234 "Randomly defined CAN frame";
CM_ SG_ 234 checksum_9_8 "8 Bit checksum for protection of frame contents";
CM_ BO_ 1075 "Randomly defined CAN frame";
CM_ SG_ 1075 checksum_9_8 "8 Bit checksum for protection of frame contents";
CM_ BO_ 845 "Randomly defined CAN frame";
CM_ SG_ 845 checksum_17_8 "8 Bit checksum for protection of frame contents";
CM_ BO_ 605 "Randomly defined CAN frame";
CM_ SG_ 605 checksum_41_8 "8 Bit checksum for protection of frame contents";
CM_ BO_ 1330 "Randomly defined CAN frame";
CM_ SG_ 1330 checksum_9_8 "8 Bit checksum for protection of frame contents";
BA_DEF_ "Author" STRING;
BA_DEF_ BO_ "frameSendMode" ENUM  "regular","event","mixed";
BA_DEF_ BO_ "sendPeriod" INT 5 10000;
BA_DEF_ BO_ "crcStartValue" INT 1 255;
BA_DEF_ BO_ "eventMinDistance" INT 5 10000;
BA_DEF_ SG_ "initialValue" FLOAT -1e38 1e38;
BA_DEF_DEF_ "Author" "http://sourceforge.net/projects/comframe/";
BA_DEF_DEF_ "frameSendMode" "regular";
BA_DEF_DEF_ "sendPeriod" 10;
BA_DEF_DEF_ "crcStartValue" 1;
BA_DEF_DEF_ "eventMinDistance" 10;
BA_DEF_DEF_ "initialValue" 0.0;
BA_ "sendPeriod" BO_ 782 20;
BA_ "crcStartValue" BO_ 782 115;
BA_ "initialValue" SG_ 782 sig_3_9 1.672277660168378E-6;
BA_ "initialValue" SG_ 782 sig_4_7 11462.27766016838;
BA_ "initialValue" SG_ 782 sig_38_9 5962.27766016838;
BA_ "initialValue" SG_ 782 sig_31_9 82322.77660168378;
BA_ "initialValue" SG_ 782 sig_44_5 0.7000000000000001;
BA_ "sendPeriod" BO_ 1125 10000;
BA_ "crcStartValue" BO_ 1125 247;
BA_ "initialValue" SG_ 1125 sig_3_7 96.0;
BA_ "initialValue" SG_ 1125 sig_6_4 -5.0;
BA_ "initialValue" SG_ 1125 sig_5_2 1.0;
BA_ "initialValue" SG_ 1125 sig_10_1 1.0;
BA_ "initialValue" SG_ 1125 sig_16_6 54.0;
BA_ "initialValue" SG_ 1125 sig_22_2 3.0;
BA_ "initialValue" SG_ 1125 sig_54_15 49555.77660168379;
BA_ "initialValue" SG_ 1125 sig_39_15 5.719477660168381;
BA_ "sendPeriod" BO_ 1842 1000;
BA_ "crcStartValue" BO_ 1842 57;
BA_ "initialValue" SG_ 1842 sig_4_4 40000.0;
BA_ "initialValue" SG_ 1842 sig_0_1 1.0;
BA_ "initialValue" SG_ 1842 sig_19_8 199.0;
BA_ "initialValue" SG_ 1842 sig_15_8 756.2277660168379;
BA_ "initialValue" SG_ 1842 sig_16_1 1.0;
BA_ "initialValue" SG_ 1842 sig_30_4 110000.0;
BA_ "initialValue" SG_ 1842 sig_27_3 6.0;
BA_ "initialValue" SG_ 1842 sig_34_6 3.200000000000002E-5;
BA_ "initialValue" SG_ 1842 sig_54_13 31227.223398316208;
BA_ "initialValue" SG_ 1842 sig_57_2 3.0;
BA_ "sendPeriod" BO_ 1429 5;
BA_ "crcStartValue" BO_ 1429 13;
BA_ "initialValue" SG_ 1429 sig_3_10 0.0677223398316209;
BA_ "initialValue" SG_ 1429 sig_7_4 0.05000000000000001;
BA_ "initialValue" SG_ 1429 sig_9_2 1.0;
BA_ "initialValue" SG_ 1429 sig_31_8 48377.22339831621;
BA_ "sendPeriod" BO_ 191 50;
BA_ "crcStartValue" BO_ 191 116;
BA_ "initialValue" SG_ 191 sig_28_4 110.0;
BA_ "initialValue" SG_ 191 sig_15_7 -15.0;
BA_ "initialValue" SG_ 191 sig_7_8 39000.0;
BA_ "initialValue" SG_ 191 sig_8_1 1.0;
BA_ "initialValue" SG_ 191 sig_18_8 0.016000000000000007;
BA_ "initialValue" SG_ 191 sig_17_2 1.0;
BA_ "initialValue" SG_ 191 sig_26_2 1.0;
BA_ "initialValue" SG_ 191 sig_44_8 6.100000000000003E-5;
BA_ "initialValue" SG_ 191 sig_43_8 2.4800000000000004;
BA_ "initialValue" SG_ 191 sig_59_4 1.0000000000000006E-6;
BA_ "initialValue" SG_ 191 sig_63_4 7.0;
BA_ "frameSendMode" BO_ 1867 2;
BA_ "sendPeriod" BO_ 1867 10000;
BA_ "eventMinDistance" BO_ 1867 100;
BA_ "crcStartValue" BO_ 1867 105;
BA_ "initialValue" SG_ 1867 sig_10_7 6.937722339831625E-5;
BA_ "initialValue" SG_ 1867 sig_15_5 1.8;
BA_ "initialValue" SG_ 1867 sig_17_10 9550.0;
BA_ "initialValue" SG_ 1867 sig_19_2 2.0;
BA_ "frameSendMode" BO_ 967 2;
BA_ "sendPeriod" BO_ 967 100;
BA_ "eventMinDistance" BO_ 967 100;
BA_ "crcStartValue" BO_ 967 39;
BA_ "initialValue" SG_ 967 sig_0_6 5.377223398316235E-7;
BA_ "initialValue" SG_ 967 sig_8_7 1.0622776601683794;
BA_ "initialValue" SG_ 967 sig_7_2 3.0;
BA_ "initialValue" SG_ 967 sig_35_9 1.5222776601683786E-4;
BA_ "initialValue" SG_ 967 sig_28_3 -4.0;
BA_ "initialValue" SG_ 967 sig_24_4 2.0;
BA_ "initialValue" SG_ 967 sig_36_5 12.0;
BA_ "initialValue" SG_ 967 sig_41_2 2.0;
BA_ "frameSendMode" BO_ 61 2;
BA_ "sendPeriod" BO_ 61 500;
BA_ "eventMinDistance" BO_ 61 100;
BA_ "crcStartValue" BO_ 61 185;
BA_ "initialValue" SG_ 61 sig_46_13 -94.0;
BA_ "initialValue" SG_ 61 sig_47_3 4.0;
BA_ "sendPeriod" BO_ 1403 500;
BA_ "crcStartValue" BO_ 1403 180;
BA_ "initialValue" SG_ 1403 sig_2_10 298.0;
BA_ "initialValue" SG_ 1403 sig_23_21 -1752.5476601683793;
BA_ "initialValue" SG_ 1403 sig_50_14 -1.4277660168376466E-8;
BA_ "frameSendMode" BO_ 1948 2;
BA_ "sendPeriod" BO_ 1948 100;
BA_ "eventMinDistance" BO_ 1948 100;
BA_ "crcStartValue" BO_ 1948 83;
BA_ "initialValue" SG_ 1948 sig_0_8 -5.9000000000000045E-6;
BA_ "initialValue" SG_ 1948 sig_21_10 -333.0;
BA_ "initialValue" SG_ 1948 sig_16_5 9.0;
BA_ "sendPeriod" BO_ 462 50;
BA_ "crcStartValue" BO_ 462 15;
BA_ "initialValue" SG_ 462 sig_7_12 -1.9182776601683793;
BA_ "initialValue" SG_ 462 sig_10_3 6.0;
BA_ "initialValue" SG_ 462 sig_11_1 1.0;
BA_ "frameSendMode" BO_ 158 2;
BA_ "sendPeriod" BO_ 158 100;
BA_ "eventMinDistance" BO_ 158 100;
BA_ "crcStartValue" BO_ 158 211;
BA_ "initialValue" SG_ 158 sig_9_34 9.973768542168386;
BA_ "initialValue" SG_ 158 sig_1_6 0.044622776601683796;
BA_ "initialValue" SG_ 158 sig_7_1 1.0;
BA_ "initialValue" SG_ 158 sig_11_2 2.0;
BA_ "initialValue" SG_ 158 sig_13_3 -1.0;
BA_ "initialValue" SG_ 158 sig_57_2 2.0;
BA_ "initialValue" SG_ 158 sig_56_1 1.0;
BA_ "initialValue" SG_ 158 sig_59_4 3.0;
BA_ "initialValue" SG_ 158 sig_63_1 1.0;
BA_ "frameSendMode" BO_ 673 2;
BA_ "sendPeriod" BO_ 673 1000;
BA_ "eventMinDistance" BO_ 673 1000;
BA_ "crcStartValue" BO_ 673 102;
BA_ "initialValue" SG_ 673 sig_13_8 3.9377223398316265E-6;
BA_ "initialValue" SG_ 673 sig_1_2 -2.0;
BA_ "initialValue" SG_ 673 sig_12_1 1.0;
BA_ "initialValue" SG_ 673 sig_21_3 6.0;
BA_ "initialValue" SG_ 673 sig_37_12 0.008280000000000004;
BA_ "initialValue" SG_ 673 sig_41_1 1.0;
BA_ "sendPeriod" BO_ 422 500;
BA_ "crcStartValue" BO_ 422 94;
BA_ "initialValue" SG_ 422 sig_13_10 625.0;
BA_ "initialValue" SG_ 422 sig_0_8 0.0014377223398316223;
BA_ "initialValue" SG_ 422 sig_14_1 1.0;
BA_ "initialValue" SG_ 422 sig_19_4 10.0;
BA_ "initialValue" SG_ 422 sig_38_17 54849.0;
BA_ "initialValue" SG_ 422 sig_53_6 32.0;
BA_ "sendPeriod" BO_ 1821 20;
BA_ "crcStartValue" BO_ 1821 217;
BA_ "initialValue" SG_ 1821 sig_22_9 -334.22776601683796;
BA_ "initialValue" SG_ 1821 sig_12_5 3.0;
BA_ "initialValue" SG_ 1821 sig_15_3 -3.0;
BA_ "initialValue" SG_ 1821 sig_26_6 0.00486227766016838;
BA_ "initialValue" SG_ 1821 sig_53_10 4.3227766016837695E-7;
BA_ "initialValue" SG_ 1821 sig_59_4 -80.0;
BA_ "frameSendMode" BO_ 1052 2;
BA_ "sendPeriod" BO_ 1052 500;
BA_ "eventMinDistance" BO_ 1052 100;
BA_ "crcStartValue" BO_ 1052 170;
BA_ "initialValue" SG_ 1052 sig_7_8 17.1;
BA_ "initialValue" SG_ 1052 sig_22_7 2.0;
BA_ "sendPeriod" BO_ 1380 20;
BA_ "crcStartValue" BO_ 1380 242;
BA_ "initialValue" SG_ 1380 sig_2_6 -5.62277660168378E-5;
BA_ "initialValue" SG_ 1380 sig_1_1 1.0;
BA_ "initialValue" SG_ 1380 sig_21_14 0.0015932000000000012;
BA_ "initialValue" SG_ 1380 sig_23_2 2.0;
BA_ "initialValue" SG_ 1380 sig_35_5 200.0;
BA_ "initialValue" SG_ 1380 sig_48_8 121.0;
BA_ "frameSendMode" BO_ 1788 2;
BA_ "sendPeriod" BO_ 1788 500;
BA_ "eventMinDistance" BO_ 1788 500;
BA_ "crcStartValue" BO_ 1788 128;
BA_ "initialValue" SG_ 1788 sig_13_14 3890.0;
BA_ "sendPeriod" BO_ 255 100;
BA_ "crcStartValue" BO_ 255 254;
BA_ "initialValue" SG_ 255 sig_29_12 -640.0;
BA_ "initialValue" SG_ 255 sig_9_7 -27.0;
BA_ "initialValue" SG_ 255 sig_8_9 0.13277223398316218;
BA_ "initialValue" SG_ 255 sig_27_4 -0.08377223398316208;
BA_ "initialValue" SG_ 255 sig_43_5 -2.9622776601683794E-4;
BA_ "sendPeriod" BO_ 586 20;
BA_ "crcStartValue" BO_ 586 217;
BA_ "initialValue" SG_ 586 sig_1_15 15158.0;
BA_ "initialValue" SG_ 586 sig_0_1 1.0;
BA_ "initialValue" SG_ 586 sig_26_8 -56.0;
BA_ "initialValue" SG_ 586 sig_24_2 3.0;
BA_ "initialValue" SG_ 586 sig_35_5 3.5622776601683794E-4;
BA_ "sendPeriod" BO_ 914 1000;
BA_ "crcStartValue" BO_ 914 108;
BA_ "initialValue" SG_ 914 sig_7_15 3791.0;
BA_ "initialValue" SG_ 914 sig_8_17 0.027690000000000017;
BA_ "initialValue" SG_ 914 sig_50_11 -33.0;
BA_ "initialValue" SG_ 914 sig_47_13 -1.599277660168378E-5;
BA_ "sendPeriod" BO_ 565 500;
BA_ "crcStartValue" BO_ 565 206;
BA_ "initialValue" SG_ 565 sig_6_24 1.0695782339831635E-4;
BA_ "sendPeriod" BO_ 53 25;
BA_ "crcStartValue" BO_ 53 6;
BA_ "initialValue" SG_ 53 sig_18_8 43.0;
BA_ "initialValue" SG_ 53 sig_15_3 -2.0;
BA_ "initialValue" SG_ 53 sig_14_1 1.0;
BA_ "initialValue" SG_ 53 sig_36_25 -0.004291910360168381;
BA_ "initialValue" SG_ 53 sig_32_4 1.2000000000000007E-4;
BA_ "initialValue" SG_ 53 sig_61_3 4.0;
BA_ "sendPeriod" BO_ 752 500;
BA_ "crcStartValue" BO_ 752 136;
BA_ "initialValue" SG_ 752 sig_5_6 29.622776601683793;
BA_ "initialValue" SG_ 752 sig_7_2 1.0;
BA_ "initialValue" SG_ 752 sig_43_19 80.18987660168382;
BA_ "initialValue" SG_ 752 sig_39_12 1523.0;
BA_ "initialValue" SG_ 752 sig_21_13 4.117223398316242E-7;
BA_ "initialValue" SG_ 752 sig_23_2 -2.0;
BA_ "initialValue" SG_ 752 sig_56_1 1.0;
BA_ "sendPeriod" BO_ 1312 500;
BA_ "crcStartValue" BO_ 1312 114;
BA_ "initialValue" SG_ 1312 sig_15_10 304.0;
BA_ "initialValue" SG_ 1312 sig_6_7 -36.622776601683796;
BA_ "initialValue" SG_ 1312 sig_7_1 1.0;
BA_ "initialValue" SG_ 1312 sig_21_6 5162.27766016838;
BA_ "frameSendMode" BO_ 863 2;
BA_ "sendPeriod" BO_ 863 50;
BA_ "eventMinDistance" BO_ 863 50;
BA_ "crcStartValue" BO_ 863 167;
BA_ "initialValue" SG_ 863 sig_0_8 4.0622776601683796E-4;
BA_ "initialValue" SG_ 863 sig_28_24 14018.953000000003;
BA_ "initialValue" SG_ 863 sig_16_8 1.0;
BA_ "initialValue" SG_ 863 sig_31_3 4.0;
BA_ "initialValue" SG_ 863 sig_48_3 6.0;
BA_ "frameSendMode" BO_ 1297 2;
BA_ "sendPeriod" BO_ 1297 10000;
BA_ "eventMinDistance" BO_ 1297 100;
BA_ "crcStartValue" BO_ 1297 145;
BA_ "initialValue" SG_ 1297 sig_5_11 1707.0;
BA_ "initialValue" SG_ 1297 sig_25_10 -419.0;
BA_ "initialValue" SG_ 1297 sig_24_5 3.2622776601683796;
BA_ "initialValue" SG_ 1297 sig_46_10 -2.4000000000000018E-5;
BA_ "initialValue" SG_ 1297 sig_47_6 -1.0000000000000006E-5;
BA_ "crcStartValue" BO_ 1535 107;
BA_ "initialValue" SG_ 1535 sig_5_14 1418.0277660168379;
BA_ "initialValue" SG_ 1535 sig_6_2 1.0;
BA_ "initialValue" SG_ 1535 sig_54_6 26.0;
BA_ "initialValue" SG_ 1535 sig_31_14 0.22930000000000011;
BA_ "initialValue" SG_ 1535 sig_47_6 -20.0;
BA_ "initialValue" SG_ 1535 sig_48_6 -12.0;
BA_ "initialValue" SG_ 1535 sig_62_3 1.0;
BA_ "initialValue" SG_ 1535 sig_63_1 1.0;
BA_ "sendPeriod" BO_ 1829 100;
BA_ "crcStartValue" BO_ 1829 226;
BA_ "initialValue" SG_ 1829 sig_30_17 157103.77660168378;
BA_ "initialValue" SG_ 1829 sig_6_10 -35.2;
BA_ "initialValue" SG_ 1829 sig_0_5 -0.9622776601683793;
BA_ "initialValue" SG_ 1829 sig_17_12 4.5042776601683806E-4;
BA_ "initialValue" SG_ 1829 sig_16_1 1.0;
BA_ "initialValue" SG_ 1829 sig_47_1 1.0;
BA_ "initialValue" SG_ 1829 sig_54_6 -6.0;
BA_ "frameSendMode" BO_ 262 2;
BA_ "sendPeriod" BO_ 262 50;
BA_ "eventMinDistance" BO_ 262 50;
BA_ "crcStartValue" BO_ 262 186;
BA_ "initialValue" SG_ 262 sig_51_2 1.0;
BA_ "initialValue" SG_ 262 sig_22_3 6.0;
BA_ "initialValue" SG_ 262 sig_8_10 -8.022277660168383E-6;
BA_ "initialValue" SG_ 262 sig_18_4 21.622776601683793;
BA_ "initialValue" SG_ 262 sig_36_15 -0.21355776601683787;
BA_ "initialValue" SG_ 262 sig_25_10 0.07722339831621028;
BA_ "initialValue" SG_ 262 sig_35_1 1.0;
BA_ "initialValue" SG_ 262 sig_54_10 545.0;
BA_ "initialValue" SG_ 262 sig_53_1 1.0;
BA_ "frameSendMode" BO_ 1208 2;
BA_ "sendPeriod" BO_ 1208 500;
BA_ "eventMinDistance" BO_ 1208 500;
BA_ "crcStartValue" BO_ 1208 29;
BA_ "initialValue" SG_ 1208 sig_15_15 28862.0;
BA_ "initialValue" SG_ 1208 sig_7_7 9.66227766016838;
BA_ "initialValue" SG_ 1208 sig_0_1 1.0;
BA_ "initialValue" SG_ 1208 sig_16_1 1.0;
BA_ "initialValue" SG_ 1208 sig_34_11 -0.009962277660168384;
BA_ "initialValue" SG_ 1208 sig_35_5 -9.0;
BA_ "frameSendMode" BO_ 1542 2;
BA_ "sendPeriod" BO_ 1542 1000;
BA_ "eventMinDistance" BO_ 1542 1000;
BA_ "crcStartValue" BO_ 1542 34;
BA_ "initialValue" SG_ 1542 sig_12_12 0.012470000000000007;
BA_ "initialValue" SG_ 1542 sig_0_7 66.22776601683796;
BA_ "initialValue" SG_ 1542 sig_7_1 1.0;
BA_ "initialValue" SG_ 1542 sig_32_8 233.77223398316204;
BA_ "crcStartValue" BO_ 1341 139;
BA_ "initialValue" SG_ 1341 sig_26_11 4.03227766016838E-4;
BA_ "initialValue" SG_ 1341 sig_19_9 1.2300000000000006E-4;
BA_ "initialValue" SG_ 1341 sig_48_8 115.0;
BA_ "sendPeriod" BO_ 1281 25;
BA_ "crcStartValue" BO_ 1281 110;
BA_ "initialValue" SG_ 1281 sig_13_17 0.0016017000000000013;
BA_ "initialValue" SG_ 1281 sig_11_4 3.162277660168379E-6;
BA_ "initialValue" SG_ 1281 sig_12_1 1.0;
BA_ "initialValue" SG_ 1281 sig_39_15 -24610.776601683792;
BA_ "initialValue" SG_ 1281 sig_40_1 1.0;
BA_ "crcStartValue" BO_ 1119 254;
BA_ "initialValue" SG_ 1119 sig_25_14 550.0;
BA_ "initialValue" SG_ 1119 sig_11_15 7.766000000000009E-7;
BA_ "initialValue" SG_ 1119 sig_15_4 -4.0;
BA_ "initialValue" SG_ 1119 sig_40_4 14.0;
BA_ "crcStartValue" BO_ 869 85;
BA_ "initialValue" SG_ 869 sig_11_8 170.0;
BA_ "initialValue" SG_ 869 sig_15_3 3.0;
BA_ "initialValue" SG_ 869 sig_16_4 3.1622776601683794E-4;
BA_ "initialValue" SG_ 869 sig_30_18 0.17482222339831632;
BA_ "sendPeriod" BO_ 1381 25;
BA_ "crcStartValue" BO_ 1381 122;
BA_ "initialValue" SG_ 1381 sig_0_54 1.9251172558091338;
BA_ "initialValue" SG_ 1381 sig_55_2 1.0;
BA_ "sendPeriod" BO_ 678 100;
BA_ "crcStartValue" BO_ 678 253;
BA_ "initialValue" SG_ 678 sig_8_7 112000.0;
BA_ "initialValue" SG_ 678 sig_15_1 1.0;
BA_ "frameSendMode" BO_ 1157 2;
BA_ "sendPeriod" BO_ 1157 1000;
BA_ "eventMinDistance" BO_ 1157 100;
BA_ "crcStartValue" BO_ 1157 56;
BA_ "initialValue" SG_ 1157 sig_0_1 1.0;
BA_ "initialValue" SG_ 1157 sig_16_7 2.9377223398316247E-4;
BA_ "sendPeriod" BO_ 152 5;
BA_ "crcStartValue" BO_ 152 205;
BA_ "initialValue" SG_ 152 sig_6_15 -1.5626776601683787;
BA_ "initialValue" SG_ 152 sig_28_20 4.011982339831628E-6;
BA_ "initialValue" SG_ 152 sig_30_2 -1.0;
BA_ "initialValue" SG_ 152 sig_31_1 1.0;
BA_ "initialValue" SG_ 152 sig_54_15 2.428700000000002E-5;
BA_ "frameSendMode" BO_ 1496 2;
BA_ "sendPeriod" BO_ 1496 10000;
BA_ "eventMinDistance" BO_ 1496 50;
BA_ "crcStartValue" BO_ 1496 106;
BA_ "initialValue" SG_ 1496 sig_1_10 0.09770000000000005;
BA_ "initialValue" SG_ 1496 sig_31_1 1.0;
BA_ "initialValue" SG_ 1496 sig_25_5 -6.0;
BA_ "initialValue" SG_ 1496 sig_40_8 1.7362277660168384;
BA_ "crcStartValue" BO_ 111 130;
BA_ "initialValue" SG_ 111 sig_30_5 0.616227766016838;
BA_ "initialValue" SG_ 111 sig_16_14 1926.0;
BA_ "initialValue" SG_ 111 sig_3_12 90.0;
BA_ "initialValue" SG_ 111 sig_0_3 5.0;
BA_ "initialValue" SG_ 111 sig_35_5 4.7622776601683805E-5;
BA_ "initialValue" SG_ 111 sig_53_9 24622.776601683792;
BA_ "initialValue" SG_ 111 sig_48_5 26.0;
BA_ "frameSendMode" BO_ 1237 2;
BA_ "sendPeriod" BO_ 1237 1000;
BA_ "eventMinDistance" BO_ 1237 1000;
BA_ "crcStartValue" BO_ 1237 17;
BA_ "initialValue" SG_ 1237 sig_0_14 10318.0;
BA_ "initialValue" SG_ 1237 sig_23_2 1.0;
BA_ "initialValue" SG_ 1237 sig_39_13 -2.127766016837677E-6;
BA_ "initialValue" SG_ 1237 sig_38_7 -123.77223398316204;
BA_ "initialValue" SG_ 1237 sig_54_3 5.0;
BA_ "sendPeriod" BO_ 509 20;
BA_ "crcStartValue" BO_ 509 90;
BA_ "initialValue" SG_ 509 sig_7_7 0.0035377223398316234;
BA_ "initialValue" SG_ 509 sig_20_26 -1.0684017601683767E-5;
BA_ "initialValue" SG_ 509 sig_23_3 4.0;
BA_ "initialValue" SG_ 509 sig_42_3 -4.0;
BA_ "frameSendMode" BO_ 927 2;
BA_ "sendPeriod" BO_ 927 1000;
BA_ "eventMinDistance" BO_ 927 1000;
BA_ "crcStartValue" BO_ 927 54;
BA_ "initialValue" SG_ 927 sig_9_14 1.0422277660168382;
BA_ "initialValue" SG_ 927 sig_8_1 1.0;
BA_ "initialValue" SG_ 927 sig_23_8 79000.0;
BA_ "initialValue" SG_ 927 sig_31_1 1.0;
BA_ "sendPeriod" BO_ 199 100;
BA_ "crcStartValue" BO_ 199 186;
BA_ "initialValue" SG_ 199 sig_3_11 1.7922776601683786E-4;
BA_ "initialValue" SG_ 199 sig_0_3 2.0;
BA_ "initialValue" SG_ 199 sig_14_2 -2.0;
BA_ "initialValue" SG_ 199 sig_28_3 1.0;
BA_ "initialValue" SG_ 199 sig_24_4 11.0;
BA_ "frameSendMode" BO_ 1601 2;
BA_ "sendPeriod" BO_ 1601 1000;
BA_ "eventMinDistance" BO_ 1601 100;
BA_ "crcStartValue" BO_ 1601 121;
BA_ "initialValue" SG_ 1601 sig_13_22 -2.150391660168378E-6;
BA_ "initialValue" SG_ 1601 sig_15_2 -1.0;
BA_ "initialValue" SG_ 1601 sig_33_6 56.0;
BA_ "frameSendMode" BO_ 1931 2;
BA_ "sendPeriod" BO_ 1931 1000;
BA_ "eventMinDistance" BO_ 1931 50;
BA_ "crcStartValue" BO_ 1931 192;
BA_ "initialValue" SG_ 1931 sig_1_14 -7.972233983162297E-6;
BA_ "initialValue" SG_ 1931 sig_6_5 8.0;
BA_ "initialValue" SG_ 1931 sig_39_8 -0.010500000000000004;
BA_ "sendPeriod" BO_ 405 100;
BA_ "crcStartValue" BO_ 405 183;
BA_ "initialValue" SG_ 405 sig_2_5 20.0;
BA_ "initialValue" SG_ 405 sig_0_2 -2.0;
BA_ "initialValue" SG_ 405 sig_26_12 3.9052776601683804E-5;
BA_ "initialValue" SG_ 405 sig_22_12 3.7202776601683796E-6;
BA_ "initialValue" SG_ 405 sig_23_1 1.0;
BA_ "initialValue" SG_ 405 sig_41_6 2.262277660168379E-4;
BA_ "initialValue" SG_ 405 sig_52_5 0.40622776601683797;
BA_ "initialValue" SG_ 405 sig_53_3 -2.0;
BA_ "sendPeriod" BO_ 1219 5;
BA_ "crcStartValue" BO_ 1219 18;
BA_ "initialValue" SG_ 1219 sig_4_25 40130.90160168379;
BA_ "initialValue" SG_ 1219 sig_0_4 6.0;
BA_ "initialValue" SG_ 1219 sig_47_2 3.0;
BA_ "initialValue" SG_ 1219 sig_40_7 3.5000000000000025E-6;
BA_ "initialValue" SG_ 1219 sig_49_14 4473.72233983162;
BA_ "sendPeriod" BO_ 788 1000;
BA_ "crcStartValue" BO_ 788 139;
BA_ "initialValue" SG_ 788 sig_1_12 3.7612776601683804E-5;
BA_ "initialValue" SG_ 788 sig_0_3 -4.0;
BA_ "initialValue" SG_ 788 sig_25_10 37.0;
BA_ "initialValue" SG_ 788 sig_31_6 4.46227766016838E-4;
BA_ "crcStartValue" BO_ 1689 138;
BA_ "initialValue" SG_ 1689 sig_12_18 44169.77660168379;
BA_ "initialValue" SG_ 1689 sig_30_1 1.0;
BA_ "initialValue" SG_ 1689 sig_43_4 1.316227766016838;
BA_ "initialValue" SG_ 1689 sig_37_2 1.0;
BA_ "initialValue" SG_ 1689 sig_38_2 3.0;
BA_ "sendPeriod" BO_ 42 500;
BA_ "crcStartValue" BO_ 42 197;
BA_ "initialValue" SG_ 42 sig_7_15 4988.0;
BA_ "initialValue" SG_ 42 sig_31_25 464.720476016838;
BA_ "initialValue" SG_ 42 sig_24_5 -16622.776601683792;
BA_ "initialValue" SG_ 42 sig_30_2 3.0;
BA_ "initialValue" SG_ 42 sig_57_6 -0.03862277660168379;
BA_ "sendPeriod" BO_ 1671 10000;
BA_ "crcStartValue" BO_ 1671 152;
BA_ "initialValue" SG_ 1671 sig_28_19 3794.6676601683794;
BA_ "initialValue" SG_ 1671 sig_7_14 113.13722339831622;
BA_ "initialValue" SG_ 1671 sig_9_4 -1.0;
BA_ "initialValue" SG_ 1671 sig_21_6 -136.22776601683796;
BA_ "initialValue" SG_ 1671 sig_27_2 2.0;
BA_ "initialValue" SG_ 1671 sig_47_1 1.0;
BA_ "initialValue" SG_ 1671 sig_55_7 -0.0020622776601683787;
BA_ "frameSendMode" BO_ 1890 2;
BA_ "sendPeriod" BO_ 1890 500;
BA_ "eventMinDistance" BO_ 1890 100;
BA_ "crcStartValue" BO_ 1890 117;
BA_ "initialValue" SG_ 1890 sig_5_8 0.02262277660168379;
BA_ "initialValue" SG_ 1890 sig_4_1 1.0;
BA_ "initialValue" SG_ 1890 sig_13_3 -4.0;
BA_ "initialValue" SG_ 1890 sig_37_23 4.5942266601683805E-4;
BA_ "initialValue" SG_ 1890 sig_31_8 0.02736227766016839;
BA_ "initialValue" SG_ 1890 sig_36_5 2062.2776601683795;
BA_ "initialValue" SG_ 1890 sig_60_4 81.6227766016838;
BA_ "frameSendMode" BO_ 434 2;
BA_ "sendPeriod" BO_ 434 10000;
BA_ "eventMinDistance" BO_ 434 100;
BA_ "crcStartValue" BO_ 434 44;
BA_ "initialValue" SG_ 434 sig_41_3 -1.0;
BA_ "initialValue" SG_ 434 sig_20_9 47.0;
BA_ "initialValue" SG_ 434 sig_5_17 357.51000000000005;
BA_ "initialValue" SG_ 434 sig_25_12 -2483.2776601683795;
BA_ "initialValue" SG_ 434 sig_27_2 3.0;
BA_ "initialValue" SG_ 434 sig_48_1 1.0;
BA_ "initialValue" SG_ 434 sig_54_2 1.0;
BA_ "sendPeriod" BO_ 1389 50;
BA_ "crcStartValue" BO_ 1389 111;
BA_ "initialValue" SG_ 1389 sig_7_8 75.0;
BA_ "initialValue" SG_ 1389 sig_17_10 887.2277660168379;
BA_ "initialValue" SG_ 1389 sig_31_4 0.004837722339831622;
BA_ "initialValue" SG_ 1389 sig_27_1 1.0;
BA_ "sendPeriod" BO_ 141 5;
BA_ "crcStartValue" BO_ 141 229;
BA_ "initialValue" SG_ 141 sig_14_12 -1.8302776601683792;
BA_ "initialValue" SG_ 141 sig_12_4 -1.0;
BA_ "initialValue" SG_ 141 sig_36_4 9.0;
BA_ "initialValue" SG_ 141 sig_31_6 2.0;
BA_ "initialValue" SG_ 141 sig_35_2 1.0;
BA_ "initialValue" SG_ 141 sig_47_20 0.04684412339831627;
BA_ "sendPeriod" BO_ 1524 500;
BA_ "crcStartValue" BO_ 1524 170;
BA_ "initialValue" SG_ 1524 sig_7_8 11.0;
BA_ "initialValue" SG_ 1524 sig_25_15 0.10240000000000006;
BA_ "initialValue" SG_ 1524 sig_17_8 5.000000000000004E-6;
BA_ "initialValue" SG_ 1524 sig_23_6 6.6227766016837805E-6;
BA_ "initialValue" SG_ 1524 sig_42_3 -2.0;
BA_ "sendPeriod" BO_ 924 10000;
BA_ "crcStartValue" BO_ 924 171;
BA_ "initialValue" SG_ 924 sig_2_8 0.18000000000000005;
BA_ "initialValue" SG_ 924 sig_15_6 23.0;
BA_ "initialValue" SG_ 924 sig_32_9 61.0;
BA_ "initialValue" SG_ 924 sig_31_15 -270.28776601683796;
BA_ "initialValue" SG_ 924 sig_51_6 -0.005262277660168381;
BA_ "initialValue" SG_ 924 sig_49_9 -225.22776601683796;
BA_ "initialValue" SG_ 924 sig_50_1 1.0;
BA_ "frameSendMode" BO_ 1022 2;
BA_ "sendPeriod" BO_ 1022 1000;
BA_ "eventMinDistance" BO_ 1022 50;
BA_ "crcStartValue" BO_ 1022 169;
BA_ "initialValue" SG_ 1022 sig_16_12 15742.776601683792;
BA_ "initialValue" SG_ 1022 sig_0_15 23280.0;
BA_ "initialValue" SG_ 1022 sig_15_1 1.0;
BA_ "initialValue" SG_ 1022 sig_28_12 0.024080000000000015;
BA_ "initialValue" SG_ 1022 sig_48_8 5.83772233983162;
BA_ "crcStartValue" BO_ 412 89;
BA_ "initialValue" SG_ 412 sig_22_23 0.09268893660168384;
BA_ "initialValue" SG_ 412 sig_9_11 -815.0;
BA_ "initialValue" SG_ 412 sig_21_2 -2.0;
BA_ "initialValue" SG_ 412 sig_45_3 1.0;
BA_ "sendPeriod" BO_ 592 500;
BA_ "crcStartValue" BO_ 592 110;
BA_ "initialValue" SG_ 592 sig_6_11 0.13517722339831628;
BA_ "initialValue" SG_ 592 sig_29_6 -14.0;
BA_ "initialValue" SG_ 592 sig_8_3 1.0;
BA_ "initialValue" SG_ 592 sig_11_1 1.0;
BA_ "initialValue" SG_ 592 sig_47_1 1.0;
BA_ "frameSendMode" BO_ 1813 2;
BA_ "sendPeriod" BO_ 1813 10000;
BA_ "eventMinDistance" BO_ 1813 1000;
BA_ "crcStartValue" BO_ 1813 20;
BA_ "initialValue" SG_ 1813 sig_21_5 0.0037622776601683797;
BA_ "initialValue" SG_ 1813 sig_15_10 0.007400000000000004;
BA_ "initialValue" SG_ 1813 sig_16_11 296.0;
BA_ "initialValue" SG_ 1813 sig_53_6 6.962277660168382E-5;
BA_ "initialValue" SG_ 1813 sig_54_1 1.0;
BA_ "frameSendMode" BO_ 1323 2;
BA_ "sendPeriod" BO_ 1323 10000;
BA_ "eventMinDistance" BO_ 1323 500;
BA_ "crcStartValue" BO_ 1323 248;
BA_ "initialValue" SG_ 1323 sig_3_15 0.03260277660168379;
BA_ "initialValue" SG_ 1323 sig_23_6 15.0;
BA_ "initialValue" SG_ 1323 sig_41_9 0.16877223398316216;
BA_ "initialValue" SG_ 1323 sig_39_7 0.004000000000000002;
BA_ "initialValue" SG_ 1323 sig_32_1 1.0;
BA_ "initialValue" SG_ 1323 sig_40_7 -0.6362277660168381;
BA_ "sendPeriod" BO_ 334 25;
BA_ "crcStartValue" BO_ 334 210;
BA_ "initialValue" SG_ 334 sig_20_9 1900.0;
BA_ "initialValue" SG_ 334 sig_14_10 -5332.27766016838;
BA_ "initialValue" SG_ 334 sig_15_1 1.0;
BA_ "initialValue" SG_ 334 sig_26_3 5.0;
BA_ "sendPeriod" BO_ 18 100;
BA_ "crcStartValue" BO_ 18 62;
BA_ "initialValue" SG_ 18 sig_13_10 6.190000000000004E-4;
BA_ "initialValue" SG_ 18 sig_9_4 5.0;
BA_ "initialValue" SG_ 18 sig_8_1 1.0;
BA_ "initialValue" SG_ 18 sig_23_1 1.0;
BA_ "frameSendMode" BO_ 793 2;
BA_ "sendPeriod" BO_ 793 500;
BA_ "eventMinDistance" BO_ 793 50;
BA_ "crcStartValue" BO_ 793 208;
BA_ "initialValue" SG_ 793 sig_8_17 51814.0;
BA_ "initialValue" SG_ 793 sig_4_10 4.347722339831622;
BA_ "initialValue" SG_ 793 sig_43_12 3321.0;
BA_ "initialValue" SG_ 793 sig_47_2 -2.0;
BA_ "frameSendMode" BO_ 1302 2;
BA_ "sendPeriod" BO_ 1302 500;
BA_ "eventMinDistance" BO_ 1302 500;
BA_ "crcStartValue" BO_ 1302 157;
BA_ "initialValue" SG_ 1302 sig_11_8 7.800000000000007E-6;
BA_ "initialValue" SG_ 1302 sig_1_9 183.0;
BA_ "initialValue" SG_ 1302 sig_10_1 1.0;
BA_ "initialValue" SG_ 1302 sig_22_4 -8.0;
BA_ "initialValue" SG_ 1302 sig_41_14 1.0101000000000009E-5;
BA_ "initialValue" SG_ 1302 sig_28_8 27662.27766016838;
BA_ "initialValue" SG_ 1302 sig_24_4 71622.77660168378;
BA_ "initialValue" SG_ 1302 sig_39_3 -2.0;
BA_ "frameSendMode" BO_ 1622 2;
BA_ "sendPeriod" BO_ 1622 10000;
BA_ "eventMinDistance" BO_ 1622 500;
BA_ "crcStartValue" BO_ 1622 226;
BA_ "initialValue" SG_ 1622 sig_5_17 -3.991223398316233E-6;
BA_ "initialValue" SG_ 1622 sig_0_5 -14.0;
BA_ "initialValue" SG_ 1622 sig_22_2 2.0;
BA_ "frameSendMode" BO_ 465 2;
BA_ "sendPeriod" BO_ 465 10000;
BA_ "eventMinDistance" BO_ 465 1000;
BA_ "crcStartValue" BO_ 465 132;
BA_ "initialValue" SG_ 465 sig_7_13 3973.0;
BA_ "frameSendMode" BO_ 1997 2;
BA_ "sendPeriod" BO_ 1997 10000;
BA_ "eventMinDistance" BO_ 1997 100;
BA_ "crcStartValue" BO_ 1997 220;
BA_ "initialValue" SG_ 1997 sig_1_5 -3.0;
BA_ "initialValue" SG_ 1997 sig_7_2 1.0;
BA_ "initialValue" SG_ 1997 sig_16_9 -3.0322776601683796;
BA_ "initialValue" SG_ 1997 sig_23_6 18.0;
BA_ "initialValue" SG_ 1997 sig_17_1 1.0;
BA_ "frameSendMode" BO_ 294 2;
BA_ "sendPeriod" BO_ 294 1000;
BA_ "eventMinDistance" BO_ 294 500;
BA_ "crcStartValue" BO_ 294 58;
BA_ "initialValue" SG_ 294 sig_12_6 48.0;
BA_ "initialValue" SG_ 294 sig_1_5 1.0;
BA_ "initialValue" SG_ 294 sig_6_2 3.0;
BA_ "initialValue" SG_ 294 sig_14_2 -1.0;
BA_ "initialValue" SG_ 294 sig_22_1 1.0;
BA_ "initialValue" SG_ 294 sig_31_15 4.02997766016838E-6;
BA_ "initialValue" SG_ 294 sig_53_13 -2864.0;
BA_ "crcStartValue" BO_ 82 45;
BA_ "initialValue" SG_ 82 sig_34_2 2.0;
BA_ "initialValue" SG_ 82 sig_7_9 4.2800000000000027E-4;
BA_ "initialValue" SG_ 82 sig_9_11 0.005092277660168381;
BA_ "initialValue" SG_ 82 sig_14_5 -0.019622776601683788;
BA_ "initialValue" SG_ 82 sig_29_10 0.957227766016838;
BA_ "initialValue" SG_ 82 sig_30_1 1.0;
BA_ "initialValue" SG_ 82 sig_35_1 1.0;
BA_ "sendPeriod" BO_ 1816 10000;
BA_ "crcStartValue" BO_ 1816 105;
BA_ "initialValue" SG_ 1816 sig_11_11 991.0;
BA_ "initialValue" SG_ 1816 sig_6_11 25.07722339831621;
BA_ "initialValue" SG_ 1816 sig_7_1 1.0;
BA_ "initialValue" SG_ 1816 sig_39_16 -30948.0;
BA_ "initialValue" SG_ 1816 sig_55_5 -0.8;
BA_ "frameSendMode" BO_ 159 2;
BA_ "sendPeriod" BO_ 159 10000;
BA_ "eventMinDistance" BO_ 159 1000;
BA_ "crcStartValue" BO_ 159 219;
BA_ "initialValue" SG_ 159 sig_21_15 0.0019435000000000014;
BA_ "initialValue" SG_ 159 sig_8_13 1498.0;
BA_ "initialValue" SG_ 159 sig_39_4 0.04000000000000001;
BA_ "initialValue" SG_ 159 sig_46_15 -15524.0;
BA_ "sendPeriod" BO_ 1449 5;
BA_ "crcStartValue" BO_ 1449 162;
BA_ "initialValue" SG_ 1449 sig_0_8 139.0;
BA_ "initialValue" SG_ 1449 sig_16_3 -4.0;
BA_ "frameSendMode" BO_ 1177 2;
BA_ "sendPeriod" BO_ 1177 10000;
BA_ "eventMinDistance" BO_ 1177 100;
BA_ "crcStartValue" BO_ 1177 193;
BA_ "initialValue" SG_ 1177 sig_22_2 -2.0;
BA_ "initialValue" SG_ 1177 sig_2_14 1.198900000000001E-4;
BA_ "initialValue" SG_ 1177 sig_1_2 -2.0;
BA_ "initialValue" SG_ 1177 sig_16_6 3.1622776601683795E-5;
BA_ "initialValue" SG_ 1177 sig_25_15 -45908.77660168379;
BA_ "initialValue" SG_ 1177 sig_48_8 -6.800000000000001;
BA_ "frameSendMode" BO_ 1356 2;
BA_ "sendPeriod" BO_ 1356 1000;
BA_ "eventMinDistance" BO_ 1356 50;
BA_ "crcStartValue" BO_ 1356 251;
BA_ "initialValue" SG_ 1356 sig_1_13 -4.972233983162235E-5;
BA_ "initialValue" SG_ 1356 sig_0_1 1.0;
BA_ "initialValue" SG_ 1356 sig_14_2 2.0;
BA_ "sendPeriod" BO_ 875 20;
BA_ "crcStartValue" BO_ 875 247;
BA_ "initialValue" SG_ 875 sig_7_10 460.0;
BA_ "initialValue" SG_ 875 sig_6_5 5.362277660168381E-4;
BA_ "initialValue" SG_ 875 sig_0_2 3.0;
BA_ "initialValue" SG_ 875 sig_18_6 0.03600000000000001;
BA_ "sendPeriod" BO_ 593 25;
BA_ "crcStartValue" BO_ 593 253;
BA_ "initialValue" SG_ 593 sig_0_7 5062.27766016838;
BA_ "initialValue" SG_ 593 sig_5_5 5.000000000000004E-7;
BA_ "initialValue" SG_ 593 sig_7_2 1.0;
BA_ "sendPeriod" BO_ 1592 1000;
BA_ "crcStartValue" BO_ 1592 101;
BA_ "initialValue" SG_ 1592 sig_39_11 6.340000000000003E-4;
BA_ "initialValue" SG_ 1592 sig_12_18 1.4185223398316222;
BA_ "initialValue" SG_ 1592 sig_13_3 5.0;
BA_ "initialValue" SG_ 1592 sig_26_3 2.0;
BA_ "initialValue" SG_ 1592 sig_33_6 9162.27766016838;
BA_ "initialValue" SG_ 1592 sig_55_6 -0.26227766016837917;
BA_ "initialValue" SG_ 1592 sig_58_6 3.0;
BA_ "initialValue" SG_ 1592 sig_56_2 1.0;
BA_ "sendPeriod" BO_ 1870 5;
BA_ "crcStartValue" BO_ 1870 164;
BA_ "initialValue" SG_ 1870 sig_21_11 1013.0;
BA_ "initialValue" SG_ 1870 sig_1_19 5611.837660168379;
BA_ "initialValue" SG_ 1870 sig_0_1 1.0;
BA_ "initialValue" SG_ 1870 sig_20_1 1.0;
BA_ "initialValue" SG_ 1870 sig_40_15 -39309.77660168379;
BA_ "frameSendMode" BO_ 1475 2;
BA_ "sendPeriod" BO_ 1475 1000;
BA_ "eventMinDistance" BO_ 1475 500;
BA_ "crcStartValue" BO_ 1475 113;
BA_ "initialValue" SG_ 1475 sig_6_7 13.0;
BA_ "initialValue" SG_ 1475 sig_25_15 3.3431776601683794E-6;
BA_ "initialValue" SG_ 1475 sig_23_12 33.85000000000001;
BA_ "initialValue" SG_ 1475 sig_51_7 1.1900000000000002;
BA_ "initialValue" SG_ 1475 sig_42_5 -0.011000000000000003;
BA_ "initialValue" SG_ 1475 sig_60_5 0.0032622776601683792;
BA_ "frameSendMode" BO_ 440 2;
BA_ "sendPeriod" BO_ 440 1000;
BA_ "eventMinDistance" BO_ 440 1000;
BA_ "crcStartValue" BO_ 440 80;
BA_ "initialValue" SG_ 440 sig_7_5 0.32622776601683795;
BA_ "initialValue" SG_ 440 sig_16_7 0.005562277660168381;
BA_ "sendPeriod" BO_ 1080 100;
BA_ "crcStartValue" BO_ 1080 148;
BA_ "initialValue" SG_ 1080 sig_31_24 8.593268000000009E-4;
BA_ "initialValue" SG_ 1080 sig_22_7 -0.030000000000000006;
BA_ "initialValue" SG_ 1080 sig_6_16 -1446.1776601683794;
BA_ "initialValue" SG_ 1080 sig_55_8 13.0;
BA_ "frameSendMode" BO_ 2000 2;
BA_ "sendPeriod" BO_ 2000 1000;
BA_ "eventMinDistance" BO_ 2000 1000;
BA_ "crcStartValue" BO_ 2000 113;
BA_ "initialValue" SG_ 2000 sig_1_16 -53.4997766016838;
BA_ "initialValue" SG_ 2000 sig_2_1 1.0;
BA_ "initialValue" SG_ 2000 sig_17_2 1.0;
BA_ "initialValue" SG_ 2000 sig_43_10 26.52277660168379;
BA_ "initialValue" SG_ 2000 sig_47_3 -2.0;
BA_ "frameSendMode" BO_ 192 1;
BA_ "eventMinDistance" BO_ 192 50;
BA_ "crcStartValue" BO_ 192 241;
BA_ "initialValue" SG_ 192 sig_10_31 4.162097800168381E-5;
BA_ "initialValue" SG_ 192 sig_9_2 2.0;
BA_ "initialValue" SG_ 192 sig_47_7 -0.00426227766016838;
BA_ "frameSendMode" BO_ 1954 2;
BA_ "sendPeriod" BO_ 1954 1000;
BA_ "eventMinDistance" BO_ 1954 50;
BA_ "crcStartValue" BO_ 1954 111;
BA_ "initialValue" SG_ 1954 sig_7_1 1.0;
BA_ "initialValue" SG_ 1954 sig_29_20 216992.0;
BA_ "initialValue" SG_ 1954 sig_16_6 3.0;
BA_ "initialValue" SG_ 1954 sig_22_1 1.0;
BA_ "initialValue" SG_ 1954 sig_31_2 -1.0;
BA_ "initialValue" SG_ 1954 sig_40_2 2.0;
BA_ "sendPeriod" BO_ 1055 1000;
BA_ "crcStartValue" BO_ 1055 86;
BA_ "initialValue" SG_ 1055 sig_0_8 -65.0;
BA_ "initialValue" SG_ 1055 sig_30_6 -7.622776601683793;
BA_ "initialValue" SG_ 1055 sig_16_13 241.87223398316206;
BA_ "initialValue" SG_ 1055 sig_40_14 7.964000000000007E-6;
BA_ "initialValue" SG_ 1055 sig_55_2 -2.0;
BA_ "frameSendMode" BO_ 1993 2;
BA_ "sendPeriod" BO_ 1993 10000;
BA_ "eventMinDistance" BO_ 1993 500;
BA_ "crcStartValue" BO_ 1993 147;
BA_ "initialValue" SG_ 1993 sig_37_13 0.011027277660168384;
BA_ "initialValue" SG_ 1993 sig_3_24 -1.1299440000000012E-5;
BA_ "initialValue" SG_ 1993 sig_0_3 4.0;
BA_ "initialValue" SG_ 1993 sig_27_5 -2.0;
BA_ "initialValue" SG_ 1993 sig_39_2 2.0;
BA_ "initialValue" SG_ 1993 sig_55_8 -10.0;
BA_ "sendPeriod" BO_ 234 5;
BA_ "crcStartValue" BO_ 234 181;
BA_ "initialValue" SG_ 234 sig_0_8 18837.72233983162;
BA_ "initialValue" SG_ 234 sig_49_15 -8.619776601683777E-4;
BA_ "initialValue" SG_ 234 sig_17_15 25323.0;
BA_ "initialValue" SG_ 234 sig_18_6 3662.2776601683795;
BA_ "initialValue" SG_ 234 sig_33_2 2.0;
BA_ "initialValue" SG_ 234 sig_44_4 -2.162277660168379E-4;
BA_ "initialValue" SG_ 234 sig_45_1 1.0;
BA_ "sendPeriod" BO_ 1075 10000;
BA_ "crcStartValue" BO_ 1075 161;
BA_ "initialValue" SG_ 1075 sig_0_8 9.377223398316239E-7;
BA_ "initialValue" SG_ 1075 sig_26_15 -0.022079776601683785;
BA_ "initialValue" SG_ 1075 sig_22_7 -646.2277660168379;
BA_ "initialValue" SG_ 1075 sig_23_3 1.0;
BA_ "initialValue" SG_ 1075 sig_42_14 -56682.77660168379;
BA_ "sendPeriod" BO_ 845 500;
BA_ "crcStartValue" BO_ 845 203;
BA_ "initialValue" SG_ 845 sig_0_15 0.002087000000000001;
BA_ "initialValue" SG_ 845 sig_25_15 0.19385776601683785;
BA_ "initialValue" SG_ 845 sig_24_1 1.0;
BA_ "initialValue" SG_ 845 sig_47_6 -0.5;
BA_ "frameSendMode" BO_ 605 2;
BA_ "sendPeriod" BO_ 605 1000;
BA_ "eventMinDistance" BO_ 605 100;
BA_ "crcStartValue" BO_ 605 159;
BA_ "initialValue" SG_ 605 sig_16_12 5840.0;
BA_ "initialValue" SG_ 605 sig_4_6 30377.223398316208;
BA_ "initialValue" SG_ 605 sig_8_6 5.76227766016838;
BA_ "initialValue" SG_ 605 sig_23_5 -4.3622776601683796E-6;
BA_ "initialValue" SG_ 605 sig_17_2 -1.0;
BA_ "initialValue" SG_ 605 sig_35_3 5.0;
BA_ "sendPeriod" BO_ 1330 50;
BA_ "crcStartValue" BO_ 1330 40;
BA_ "initialValue" SG_ 1330 sig_4_5 6.16227766016838;
BA_ "initialValue" SG_ 1330 sig_7_2 -1.0;
BA_ "initialValue" SG_ 1330 sig_21_12 -0.004442776601683775;
BA_ "initialValue" SG_ 1330 sig_23_2 2.0;
BA_ "initialValue" SG_ 1330 sig_25_2 -1.0;
